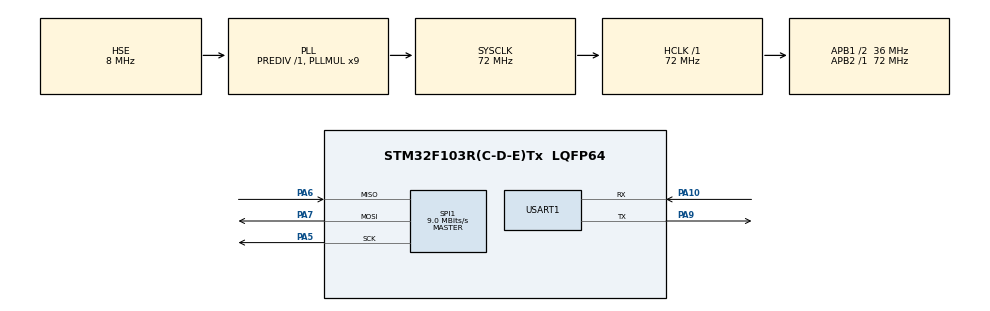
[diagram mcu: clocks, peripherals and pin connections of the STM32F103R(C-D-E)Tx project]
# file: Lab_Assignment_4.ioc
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Mcu.Family=STM32F1
Mcu.Name=STM32F103R(C-D-E)Tx
Mcu.Package=LQFP64
NVIC.PriorityGroup=NVIC_PRIORITYGROUP_4
PA10.Mode=Asynchronous
PA10.Signal=USART1_RX
PA13.Mode=Serial_Wire
PA13.Signal=SYS_JTMS-SWDIO
PA14.Mode=Serial_Wire
PA14.Signal=SYS_JTCK-SWCLK
PA5.Mode=Full_Duplex_Master
PA5.Signal=SPI1_SCK
PA6.Mode=Full_Duplex_Master
PA6.Signal=SPI1_MISO
PA7.Mode=Full_Duplex_Master
PA7.Signal=SPI1_MOSI
PA9.Mode=Asynchronous
PA9.Signal=USART1_TX
PD0-OSC_IN.Mode=HSE-External-Oscillator
PD0-OSC_IN.Signal=RCC_OSC_IN
PD1-OSC_OUT.Mode=HSE-External-Oscillator
PD1-OSC_OUT.Signal=RCC_OSC_OUT
ProjectManager.HeapSize=0x200
ProjectManager.StackSize=0x400
ProjectManager.TargetToolchain=STM32CubeIDE
RCC.AHBFreq_Value=72000000
RCC.APB1CLKDivider=RCC_HCLK_DIV2
RCC.APB1Freq_Value=36000000
RCC.APB1TimFreq_Value=72000000
RCC.APB2Freq_Value=72000000
RCC.APB2TimFreq_Value=72000000
RCC.HCLKFreq_Value=72000000
RCC.PLLMUL=RCC_PLL_MUL9
RCC.PLLSourceVirtual=RCC_PLLSOURCE_HSE
RCC.SYSCLKFreq_VALUE=72000000
RCC.SYSCLKSource=RCC_SYSCLKSOURCE_PLLCLK
RCC.USBFreq_Value=72000000
SPI1.BaudRatePrescaler=SPI_BAUDRATEPRESCALER_8
SPI1.CalculateBaudRate=9.0 MBits/s
SPI1.Direction=SPI_DIRECTION_2LINES
SPI1.Mode=SPI_MODE_MASTER
SPI1.VirtualType=VM_MASTER
USART1.VirtualMode=VM_ASYNC
board=custom

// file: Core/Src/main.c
/* USER CODE BEGIN Header */
/**
  ******************************************************************************
  * @file           : main.c
  * @brief          : Main program body
  ******************************************************************************
  * @attention
  *
  * Copyright (c) 2022 STMicroelectronics.
  * All rights reserved.
  *
  * This software is licensed under terms that can be found in the LICENSE file
  * in the root directory of this software component.
  * If no LICENSE file comes with this software, it is provided AS-IS.
  *
  ******************************************************************************
  */
/* USER CODE END Header */
#include "main.h"

/* USER CODE BEGIN Includes */

/* Private includes ----------------------------------------------------------*/
/* USER CODE BEGIN Includes */
#include "sys.h"
#include "delay.h"
#include "stdlib.h"
//#include "usart.h"
#include "led.h"
#include "key.h"
#include "lcd.h"
//#include "usmart.h"
#include "touch.h"
#include "24cxx.h"
#include "24l01.h" //通信驱动 基于spi进行通信
/* USER CODE END Includes */

/* USER CODE BEGIN PD */
unsigned char DATA_TO_SEND[800];
int state_num = 0;
u8 STATE[30];
UART_HandleTypeDef huart1;

const unsigned char gImage_barrier[2088] = { 0X00,0X10,0X1A,0X00,0X28,0X00,0X01,0X1B,
0X00,0X00,0XFF,0XFF,0XFF,0XFF,0XFF,0XFF,0XFF,0XFF,0XFF,0XFF,0XFF,0XFF,0XFF,0XFF,
0XFF,0XFF,0XFF,0XFF,0XFF,0XFF,0XFF,0XFF,0XFF,0XFF,0XFF,0XFF,0XFF,0XFF,0XFF,0XFF,
0XFF,0XFF,0XFF,0XFF,0XFF,0XFF,0XFF,0XFF,0XFF,0XFF,0XFF,0XFF,0XFF,0XFF,0XFF,0XFF,
0XFF,0XFF,0XFF,0XFF,0XFF,0XFF,0X00,0X00,0XFF,0XFF,0XFF,0XFF,0XFF,0XFF,0XFF,0XFF,
0XFF,0XFF,0XFF,0XFF,0XFF,0XFF,0XFF,0XFF,0XFF,0XFF,0XFF,0XFF,0XFF,0XFF,0XFF,0XFF,
0XFF,0XFF,0XFF,0XFF,0XFF,0XFF,0XFF,0XFF,0XFF,0XFF,0XFF,0XFF,0XFF,0XFF,0XFF,0XFF,
0XFF,0XFF,0XFF,0XFF,0XFF,0XFF,0XFF,0XFF,0XFF,0XFF,0X00,0X00,0XFF,0XFF,0XFF,0XFF,
0XFF,0XFF,0XFF,0XFF,0XFF,0XFF,0XFF,0XFF,0XFF,0XFF,0XFF,0XFF,0XFF,0XFF,0XFF,0XFF,
0XFF,0XFF,0XFF,0XFF,0XFF,0XFF,0X65,0X29,0XFF,0XFF,0XFF,0XFF,0XFF,0XFF,0XFF,0XFF,
0XFF,0XFF,0XFF,0XFF,0XFF,0XFF,0XFF,0XFF,0XFF,0XFF,0XFF,0XFF,0XFF,0XFF,0XFF,0XFF,
0X00,0X00,0XFF,0XFF,0XFF,0XFF,0XFF,0XFF,0XFF,0XFF,0XFF,0XFF,0XFF,0XFF,0XFF,0XFF,
0XFF,0XFF,0XFF,0XFF,0XF7,0XBD,0XFF,0XFF,0X28,0X42,0XFF,0XFF,0XFF,0XFF,0X7D,0XAF,
0X5C,0X4F,0XFF,0XFF,0XFF,0XFF,0XFF,0XFF,0XFF,0XFF,0XFF,0XFF,0XFF,0XFF,0XFF,0XFF,
0XFF,0XFF,0XFF,0XFF,0XFF,0XFF,0X00,0X00,0XFF,0XFF,0XFF,0XFF,0XFF,0XFF,0XFF,0XFF,
0XFF,0XFF,0XFF,0XFF,0XFF,0XFF,0X71,0X8C,0XFF,0XFF,0XFF,0XFF,0XD7,0XBD,0XFF,0XFF,
0XF7,0X45,0XAE,0X03,0XAE,0X03,0X4F,0X0C,0X05,0X5A,0XFF,0XFF,0XFF,0XFF,0XFF,0XFF,
0XFF,0XFF,0XFF,0XFF,0XFF,0XFF,0XFF,0XFF,0XFF,0XFF,0X00,0X00,0XFF,0XFF,0XFF,0XFF,
0XFF,0XFF,0XFF,0XFF,0XFF,0XFF,0X9E,0XF7,0X00,0X00,0XFF,0XFF,0XFF,0XFF,0X00,0X00,
0XFF,0XFF,0XFF,0XFF,0XFF,0XFF,0X30,0X14,0X2A,0X02,0X8B,0X33,0X4C,0X4B,0XFF,0XFF,
0XFF,0XFF,0XFF,0XFF,0XFF,0XFF,0XFF,0XFF,0XFF,0XFF,0XFF,0XFF,0XFF,0XFF,0XFF,0XFF,
0X00,0X00,0XFF,0XFF,0XFF,0XFF,0XFF,0XFF,0XFF,0XFF,0X00,0X00,0XFF,0XFF,0XFF,0XFF,
0X0D,0X8C,0X2C,0X63,0XFF,0XFF,0XFF,0XFF,0XFF,0XFF,0X49,0X02,0X89,0X02,0XE7,0X7A,
0X00,0X00,0XFF,0XFF,0XFF,0XFF,0XFF,0XFF,0XFF,0XFF,0XFF,0XFF,0XFF,0XFF,0XFF,0XFF,
0XFF,0XFF,0XFF,0XFF,0X00,0X00,0XFF,0XFF,0XFF,0XFF,0XFF,0XFF,0X00,0X00,0XFF,0XFF,
0XFF,0XFF,0XFF,0XFF,0X31,0X5C,0XEF,0X7B,0XFF,0XFF,0XFF,0XFF,0X6A,0X42,0X69,0X01,
0X72,0XDE,0X86,0X3A,0X0D,0X23,0XFF,0XFF,0XFF,0XFF,0XFF,0XFF,0XFF,0XFF,0XFF,0XFF,
0XFF,0XFF,0XFF,0XFF,0XFF,0XFF,0XFF,0XFF,0XFF,0XFF,0X00,0X00,0XFF,0XFF,0XCE,0XD5,
0XA2,0X10,0XFF,0XFF,0XFF,0XFF,0XFF,0XFF,0XCF,0X5B,0X4E,0X4B,0X11,0X3C,0X46,0X21,
0X0E,0X8C,0X0D,0XC5,0X66,0X62,0XE5,0X00,0XFF,0XFF,0XFF,0XFF,0XFF,0XFF,0XFF,0XFF,
0XFF,0XFF,0XFF,0XFF,0XFF,0XFF,0XFF,0XFF,0XFF,0XFF,0XFF,0XFF,0XFF,0XFF,0XFF,0XFF,
0X4D,0XF6,0X69,0X83,0XFF,0XFF,0XFF,0XFF,0XFF,0XFF,0XFE,0XFF,0X59,0XAE,0X07,0X32,
0X62,0X00,0X75,0X85,0XA5,0X31,0X00,0X39,0X27,0X4A,0XFF,0XFF,0X00,0X00,0XFF,0XFF,
0XFF,0XFF,0XFF,0XFF,0XFF,0XFF,0XFF,0XFF,0XFF,0XFF,0XFF,0XFF,0XFF,0XFF,0XFF,0XFF,
0XFF,0XFF,0XFF,0XFF,0XCC,0XF5,0X00,0X00,0XFF,0XFF,0XFF,0XFF,0XFF,0XFF,0X3D,0XEF,
0XAE,0X6B,0XA6,0X9B,0XA6,0X29,0X67,0X19,0XA7,0X21,0X62,0X29,0X84,0X21,0XFF,0XFF,
0XFF,0XFF,0XFF,0XFF,0XFF,0XFF,0XFF,0XFF,0XFF,0XFF,0X18,0XC6,0XFF,0XFF,0XFF,0XFF,
0XFF,0XFF,0XFF,0XFF,0XFF,0XFF,0X55,0XE6,0XAD,0XED,0X00,0X00,0XFF,0XFF,0X88,0X19,
0X2A,0X0A,0X2A,0X39,0XE9,0X6A,0XA7,0X3A,0X66,0X21,0X88,0X09,0XA8,0X01,0X87,0X11,
0XFF,0XFF,0X66,0X11,0XFF,0XFF,0XFF,0XFF,0XFF,0XFF,0XFF,0XFF,0X8F,0XF5,0X00,0X00,
0XFF,0XFF,0XFF,0XFF,0XFF,0XFF,0XFF,0XFF,0XFF,0XFF,0XC9,0XAB,0X89,0XCC,0X54,0XA5,
0X04,0X09,0X6F,0X2B,0X33,0X3C,0X6D,0X63,0X51,0X54,0X68,0X11,0XE2,0X18,0X09,0X12,
0X88,0X01,0XFF,0XFF,0X88,0X21,0X00,0X00,0XFF,0XFF,0XFF,0XFF,0XFF,0XFF,0XFF,0XFF,
0X89,0XDC,0XE2,0X82,0XFF,0XFF,0XFF,0XFF,0XFF,0XFF,0XFF,0XFF,0XFF,0XFF,0X83,0X7A,
0XC6,0XAB,0X87,0X19,0X4B,0X0A,0XCD,0X1A,0X75,0X1C,0X6F,0X3B,0X0F,0X23,0XA8,0X29,
0X86,0X21,0X4B,0X12,0XC9,0X01,0XFF,0XFF,0X47,0X01,0X00,0X00,0XFF,0XFF,0XFF,0XFF,
0XFF,0XFF,0XFF,0XFF,0X69,0XD4,0XA0,0X72,0XFF,0XFF,0XFF,0XFF,0XFF,0XFF,0XFF,0XFF,
0XFF,0XFF,0X00,0X7A,0X0B,0XDD,0X45,0X11,0X0A,0X0A,0X10,0X1B,0X2F,0X54,0X89,0X4A,
0XC7,0X39,0X47,0X5A,0X89,0X4A,0X2F,0X1B,0XFF,0XFF,0X6E,0X43,0X6C,0X0A,0XC5,0X00,
0XFF,0XFF,0XFF,0XFF,0XFF,0XFF,0X0A,0XA4,0X43,0XAB,0X81,0X72,0XFF,0XFF,0XFF,0XFF,
0XFF,0XFF,0XFF,0XFF,0XFF,0XFF,0X80,0X61,0X33,0XFF,0X67,0X2A,0X2B,0X12,0X6D,0X3B,
0X2C,0XD4,0X2C,0XBC,0XCB,0X93,0XA9,0X52,0X6E,0X23,0XFF,0XFF,0X91,0X13,0X8F,0X33,
0XAF,0X1B,0X00,0X00,0XFF,0XFF,0XFF,0XFF,0XFF,0XFF,0X07,0XBC,0XC1,0X92,0X82,0X62,
0XFF,0XFF,0XFF,0XFF,0XFF,0XFF,0XFF,0XFF,0XFF,0XFF,0XE0,0X79,0XE9,0XDC,0X67,0X3A,
0X69,0X22,0XAB,0X5B,0XEC,0XD4,0X4C,0X94,0X2B,0XB4,0XEB,0X93,0XEF,0X23,0XFF,0XFF,
0X0F,0X13,0X8F,0X23,0X4D,0X23,0X00,0X00,0XFF,0XFF,0X4F,0XF7,0XA8,0XCC,0X45,0X9B,
0X60,0X7A,0X00,0X00,0XFF,0XFF,0XFF,0XFF,0XFF,0XFF,0XFF,0XFF,0XFF,0XFF,0X41,0X82,
0X87,0XA3,0X63,0X42,0XA8,0X6A,0X48,0X7B,0XEA,0XEC,0XCB,0XE4,0X6B,0XBC,0X49,0X63,
0XFF,0XFF,0XA5,0XAB,0XAB,0X12,0XED,0X1A,0XCC,0X42,0X8A,0X73,0X6E,0XF6,0X6B,0XE5,
0X24,0XA3,0X64,0XAB,0X41,0X72,0X29,0X3A,0XFF,0XFF,0XFF,0XFF,0XFF,0XFF,0XFF,0XFF,
0XFF,0XFF,0X08,0X7B,0XC5,0X82,0X01,0X4A,0XA4,0X92,0XAA,0XA3,0XEC,0XEC,0XA5,0X6A,
0XCC,0X53,0XFF,0XFF,0X6F,0XD6,0XA3,0X8A,0XC7,0X11,0X06,0X32,0X0E,0XEE,0XEB,0XD4,
0X89,0XDC,0X62,0X82,0X86,0XAB,0X01,0X62,0X44,0X5A,0XA4,0X00,0XFF,0XFF,0XFF,0XFF,
0XFF,0XFF,0XFF,0XFF,0XCE,0X02,0XC4,0X21,0XC1,0X59,0X81,0X51,0XE5,0XA2,0X0A,0XBC,
0X89,0X93,0X27,0X6A,0XAA,0X8B,0XFF,0XFF,0XA4,0XB3,0X64,0X7A,0XA7,0X72,0X68,0XA3,
0XC7,0XB3,0XE7,0XB3,0X25,0X9B,0XE4,0X8A,0XC1,0X59,0X02,0X5A,0X24,0X29,0X45,0X4A,
0XFF,0XFF,0XFF,0XFF,0XD9,0X0D,0X50,0X03,0X8B,0X02,0X45,0X29,0XC3,0X59,0X21,0X39,
0XC6,0XAB,0X29,0X83,0X65,0X92,0X08,0XB4,0XFF,0XFF,0X02,0X62,0X42,0X6A,0XA2,0X51,
0X64,0X62,0XE3,0X49,0XA2,0X41,0XC4,0X82,0X66,0X5A,0XC4,0X11,0X03,0X11,0XEB,0X52,
0XE7,0X31,0X86,0X29,0XFF,0XFF,0X2F,0X03,0X76,0X04,0XD2,0X0B,0XFF,0XFF,0XFF,0XFF,
0XFF,0XFF,0XE2,0X10,0X62,0X72,0XA3,0X82,0X21,0X72,0XE0,0X40,0XFF,0XFF,0XE4,0X82,
0X20,0X41,0X60,0X31,0X45,0X29,0X47,0X52,0XA3,0X72,0XC6,0X41,0X05,0X11,0X05,0X01,
0XCC,0X52,0XE8,0X31,0X07,0X09,0X00,0X00,0XFF,0XFF,0XBB,0X5E,0X00,0X00,0X5D,0X1F,
0XFF,0XFF,0XFF,0XFF,0XFF,0XFF,0X26,0X11,0XA4,0X7A,0XC1,0X59,0X01,0X39,0XFF,0XFF,
0XE0,0X38,0XE0,0X38,0XC3,0X49,0X00,0X31,0XE1,0X20,0X02,0X19,0X0A,0X3A,0XA8,0X29,
0X65,0X10,0X4A,0X42,0XC9,0X21,0X45,0X11,0X6B,0X02,0X00,0X00,0XFF,0XFF,0X00,0X00,
0XFF,0XFF,0XFF,0XFF,0XFF,0XFF,0XFF,0XFF,0XFF,0XFF,0X87,0X21,0XE2,0X59,0X64,0X29,
0XFF,0XFF,0XA4,0X49,0XC0,0X38,0XA3,0X08,0XC3,0X00,0XC4,0X00,0XA8,0X11,0X2A,0X32,
0XA9,0X21,0X46,0X19,0X46,0X21,0X46,0X21,0X6B,0X0A,0XCC,0X02,0X8C,0X02,0X4B,0X0A,
0XFF,0XFF,0XFF,0XFF,0XFF,0XFF,0XFF,0XFF,0XFF,0XFF,0XFF,0XFF,0XFF,0XFF,0XDF,0XFF,
0XA3,0X51,0X05,0X21,0XFF,0XFF,0XE1,0X30,0X65,0X31,0X09,0X3A,0XE9,0X31,0X8B,0X42,
0X8C,0X52,0X2A,0X3A,0X88,0X21,0X89,0X11,0X08,0X3A,0XE6,0X72,0X46,0X32,0X2A,0X02,
0X0B,0X02,0X00,0X00,0XFF,0XFF,0XFF,0XFF,0XFF,0XFF,0XFF,0XFF,0XFF,0XFF,0XFF,0XFF,
0XFF,0XFF,0XFF,0XFF,0X86,0X31,0XFF,0XFF,0XA4,0X51,0X83,0X18,0XE6,0X00,0XA5,0X00,
0XA5,0X08,0X0A,0X0A,0XE8,0X09,0XC7,0X09,0XC5,0X09,0XAA,0X09,0XE9,0X11,0X85,0X19,
0XA6,0X29,0X8B,0X02,0X0A,0X02,0X00,0X00,0XFF,0XFF,0XFF,0XFF,0XFF,0XFF,0XFF,0XFF,
0XFF,0XFF,0XFF,0XFF,0XFF,0XFF,0XFF,0XFF,0XFF,0XFF,0X83,0X00,0XA3,0X10,0XC2,0X28,
0X06,0X01,0XE9,0X21,0XE7,0X08,0XB6,0X02,0X0E,0X02,0X29,0X0A,0XC7,0X09,0XC5,0X09,
0XA8,0X11,0XA7,0X09,0X86,0X01,0XED,0X0A,0XED,0X02,0XE7,0X39,0XFF,0XFF,0XFF,0XFF,
0XFF,0XFF,0XFF,0XFF,0XFF,0XFF,0XFF,0XFF,0XFF,0XFF,0XFF,0XFF,0XFF,0XFF,0X25,0X19,
0X67,0X21,0X86,0X29,0X0A,0X32,0X07,0X09,0XC6,0X00,0X6D,0X02,0XB0,0X02,0X6E,0X02,
0X29,0X0A,0X07,0X0A,0XA5,0X09,0X87,0X09,0XA7,0X01,0X90,0X13,0XEE,0X02,0XFF,0XFF,
0XFF,0XFF,0XFF,0XFF,0XFF,0XFF,0XFF,0XFF,0XFF,0XFF,0X2C,0X63,0X00,0X00,0XFF,0XFF,
0X49,0X0A,0XA7,0X21,0X06,0X11,0X47,0X19,0XE6,0X00,0X68,0X01,0XCA,0X01,0XA9,0X01,
0XAD,0X02,0X70,0X02,0X4C,0X02,0X28,0X0A,0XE6,0X09,0X86,0X09,0XA7,0X09,0XD1,0X03,
0X2E,0X0B,0XFF,0XFF,0XFF,0XFF,0XFF,0XFF,0XFF,0XFF,0XFF,0XFF,0XFF,0XFF,0XFF,0XFF,
0XFF,0XFF,0XFF,0XFF,0XFF,0XFF,0XA6,0X19,0X80,0X18,0XE4,0X08,0X25,0X19,0XC9,0X09,
0X6C,0X0A,0X49,0X01,0XC9,0X02,0X8D,0X02,0X6E,0X02,0X49,0X02,0XE7,0X09,0XA5,0X01,
0X88,0X01,0XF0,0X03,0X6F,0X03,0XFF,0XFF,0XFF,0XFF,0XFF,0XFF,0XFF,0XFF,0XFF,0XFF,
0XFF,0XFF,0XFF,0XFF,0XFF,0XFF,0XFF,0XFF,0XFF,0XFF,0XFF,0XFF,0X00,0X39,0X21,0X19,
0X42,0X29,0X65,0X01,0X0A,0X02,0X89,0X01,0X48,0X02,0X6A,0X02,0X2C,0X02,0X28,0X02,
0X07,0X0A,0XA5,0X01,0XCA,0X01,0X53,0X04,0X00,0X00,0XFF,0XFF,0XFF,0XFF,0XFF,0XFF,
0XFF,0XFF,0XFF,0XFF,0XFF,0XFF,0XFF,0XFF,0XFF,0XFF,0XFF,0XFF,0XFF,0XFF,0XFF,0XFF,
0X00,0X00,0XA5,0X19,0XC5,0X09,0X83,0X31,0XE9,0X01,0XC9,0X01,0X4A,0X02,0X6B,0X02,
0X2E,0X02,0X0A,0X02,0X07,0X02,0X85,0X01,0XDA,0X04,0XF8,0X04,0X90,0X13,0XFF,0XFF,
0XFF,0XFF,0XFF,0XFF,0XFF,0XFF,0XFF,0XFF,0XFF,0XFF,0XFF,0XFF,0XFF,0XFF,0XFF,0XFF,
0XFF,0XFF,0XFF,0XFF,0XFF,0XFF,0XFF,0XFF,0XFF,0XFF,0X00,0X00,0X8E,0X73,0XFF,0XFF,
0XFF,0XFF,0X9E,0XEF,0X4D,0X02,0X00,0X00,0X7D,0XEF,0X3C,0X06,0X98,0X04,0XD8,0X04,
0X13,0X04,0XFF,0XFF,0XFF,0XFF,0XFF,0XFF,0XFF,0XFF,0XFF,0XFF,0XFF,0XFF,0XFF,0XFF,
0XFF,0XFF,0XFF,0XFF,0XFF,0XFF,0XFF,0XFF,0XFF,0XFF,0XFF,0XFF,0XFF,0XFF,0XFF,0XFF,
0XFF,0XFF,0XFF,0XFF,0XFF,0XFF,0X2B,0X02,0X4A,0X02,0XFF,0XFF,0XFF,0XFF,0XA7,0X01,
0X89,0X01,0X79,0X05,0X91,0X03,0XFF,0XFF,0XFF,0XFF,0XFF,0XFF,0XFF,0XFF,0XFF,0XFF,
0XFF,0XFF,0XFF,0XFF,0XFF,0XFF,0XFF,0XFF,0XFF,0XFF,0XFF,0XFF,0XFF,0XFF,0XFF,0XFF,
0XFF,0XFF,0XFF,0XFF,0XFF,0XFF,0XFF,0XFF,0XFC,0XD6,0XCD,0X01,0X00,0X00,0XFF,0XFF,
0X9A,0X46,0X87,0X01,0XF0,0X6B,0X6F,0X03,0X34,0X0C,0XFF,0XFF,0XFF,0XFF,0XFF,0XFF,
0XFF,0XFF,0XFF,0XFF,0XFF,0XFF,0XFF,0XFF,0XFF,0XFF,0XFF,0XFF,0XFF,0XFF,0XFF,0XFF,
0XFF,0XFF,0XFF,0XFF,0XFF,0XFF,0XFF,0XFF,0X29,0X02,0X2F,0X02,0X00,0X00,0X00,0X00,
0XFF,0XFF,0XFF,0XFF,0XA5,0X01,0XC5,0X00,0X35,0X3D,0X3B,0X06,0X13,0X04,0XBA,0XD6,
0XFF,0XFF,0XFF,0XFF,0XFF,0XFF,0XFF,0XFF,0XFF,0XFF,0XFF,0XFF,0XFF,0XFF,0XFF,0XFF,
0XFF,0XFF,0XFF,0XFF,0XFF,0XFF,0XFF,0XFF,0XFF,0XFF,0X4F,0X2B,0X00,0X00,0X5D,0XEF,
0XFF,0XFF,0XFF,0XFF,0XFF,0XFF,0XFF,0XFF,0XAB,0X09,0X2A,0X12,0X00,0X00,0X00,0X00,
0X6E,0X03,0XBA,0XD6,0XFF,0XFF,0XFF,0XFF,0XFF,0XFF,0XFF,0XFF,0XFF,0XFF,0XFF,0XFF,
0XFF,0XFF,0XFF,0XFF,0XFF,0XFF,0XFF,0XFF,0XFF,0XFF,0XED,0X22,0XFF,0XFF,0XFF,0XFF,
0XFF,0XFF,0XFF,0XFF,0XFF,0XFF,0XFF,0XFF,0XFF,0XFF,0XAB,0X01,0X08,0X0A,0X0D,0X02,
0XFF,0XFF,0XFF,0XFF,0X00,0X00,0XFF,0XFF,0XFF,0XFF,0XFF,0XFF,0XFF,0XFF,0XFF,0XFF,
0XFF,0XFF,0XFF,0XFF,0XFF,0XFF,0XFF,0XFF,0XFF,0XFF,0XFF,0XFF,0XFF,0XFF,0XFF,0XFF,
0XFF,0XFF,0XFF,0XFF,0XFF,0XFF,0XFF,0XFF,0XFF,0XFF,0XFF,0XFF,0X89,0X01,0X0B,0X1A,
0X6F,0X2A,0X8A,0X09,0XEF,0X7B,0XFF,0XFF,0X00,0X00,0XFF,0XFF,0XFF,0XFF,0XFF,0XFF,
0XFF,0XFF,0XFF,0XFF,0XFF,0XFF,0XFF,0XFF,0XFF,0XFF,0XFF,0XFF,0XFF,0XFF,0XFF,0XFF,
0XFF,0XFF,0XFF,0XFF,0XFF,0XFF,0XFF,0XFF,0XFF,0XFF,0XFF,0XFF,0X69,0X4A,0X96,0XB5,
0XFF,0XFF,0XFF,0XFF,0XFF,0XFF,0XFF,0XFF,0X7D,0XEF,0XFF,0XFF,0XFF,0XFF,0XFF,0XFF,
};
const unsigned char gImage_player[1768] = { 0X00,0X10,0X28,0X00,0X16,0X00,0X01,0X1B,
0X00,0X00,0XFF,0XFF,0XFF,0XFF,0XFF,0XFF,0XFF,0XFF,0XFF,0XFF,0XFF,0XFF,0XFF,0XFF,
0XFF,0XFF,0XFF,0XFF,0XFF,0XFF,0XFF,0XFF,0XFF,0XFF,0XFF,0XFF,0XFF,0XFF,0XFF,0XFF,
0XFF,0XFF,0XFF,0XFF,0XFF,0XFF,0XFF,0XFF,0XFF,0XFF,0XFF,0XFF,0XFF,0XFF,0XFF,0XFF,
0XFF,0XFF,0XFF,0XFF,0XFF,0XFF,0XFF,0XFF,0XFF,0XFF,0XFF,0XFF,0XFF,0XFF,0XFF,0XFF,
0XFF,0XFF,0XFF,0XFF,0XFF,0XFF,0XFF,0XFF,0XFF,0XFF,0XFF,0XFF,0XFF,0XFF,0XFF,0XFF,
0XFF,0XFF,0X00,0X00,0X00,0X00,0XFF,0XFF,0XFF,0XFF,0XFF,0XFF,0XFF,0XFF,0XFF,0XFF,
0XFF,0XFF,0XFF,0XFF,0XFF,0XFF,0XFF,0XFF,0XFF,0XFF,0XFF,0XFF,0XFF,0XFF,0XFF,0XFF,
0XFF,0XFF,0XFF,0XFF,0XFF,0XFF,0XFF,0XFF,0XFF,0XFF,0XFF,0XFF,0XFF,0XFF,0XFF,0XFF,
0XFF,0XFF,0XDA,0XDE,0X58,0XC6,0XCC,0X29,0X24,0X42,0XF1,0X53,0XFF,0XFF,0XFF,0XFF,
0XFF,0XFF,0XFF,0XFF,0XFF,0XFF,0XFF,0XFF,0XFF,0XFF,0XFF,0XFF,0XFF,0XFF,0XFF,0XFF,
0XFF,0XFF,0XFF,0XFF,0XFF,0XFF,0X00,0X00,0X00,0X00,0XFF,0XFF,0XFF,0XFF,0XFF,0XFF,
0XFF,0XFF,0XFF,0XFF,0XFF,0XFF,0XFF,0XFF,0XFF,0XFF,0XFF,0XFF,0XFF,0XFF,0XFF,0XFF,
0XFF,0XFF,0XFF,0XFF,0XFF,0XFF,0XFF,0XFF,0XFF,0XFF,0XFF,0XFF,0XFF,0XFF,0XFF,0XFF,
0X58,0X85,0X6D,0X32,0XA8,0X19,0XCE,0X73,0X2D,0XA5,0X48,0X42,0XFF,0XFF,0XFF,0XFF,
0XFF,0XFF,0XFF,0XFF,0XFF,0XFF,0XFF,0XFF,0XFF,0XFF,0XFF,0XFF,0XFF,0XFF,0XFF,0XFF,
0XFF,0XFF,0XFF,0XFF,0XFF,0XFF,0XFF,0XFF,0XFF,0XFF,0X00,0X00,0X00,0X00,0XFF,0XFF,
0XFF,0XFF,0XFF,0XFF,0XFF,0XFF,0XFF,0XFF,0XFF,0XFF,0XFF,0XFF,0XFF,0XFF,0XFF,0XFF,
0XFF,0XFF,0XFF,0XFF,0XFF,0XFF,0XFF,0XFF,0XFF,0XFF,0X71,0X43,0XF4,0X5B,0XF0,0X3A,
0XCF,0X3A,0X4B,0X3A,0X00,0X00,0X4E,0X53,0X03,0X19,0XA1,0X39,0X00,0X00,0XFF,0XFF,
0XFF,0XFF,0XFF,0XFF,0XFF,0XFF,0XFF,0XFF,0XFF,0XFF,0XFF,0XFF,0XFF,0XFF,0XFF,0XFF,
0XFF,0XFF,0XFF,0XFF,0XFF,0XFF,0XFF,0XFF,0XFF,0XFF,0XFF,0XFF,0XFF,0XFF,0X00,0X00,
0X00,0X00,0XFF,0XFF,0XFF,0XFF,0XFF,0XFF,0XFF,0XFF,0XFF,0XFF,0XFF,0XFF,0XFF,0XFF,
0XFF,0XFF,0XFF,0XFF,0XFF,0XFF,0X00,0X00,0XFF,0XFF,0X7E,0XEF,0X11,0X4B,0XCF,0X42,
0XCF,0X3A,0X00,0X00,0XFF,0XFF,0X2F,0X53,0XA2,0X18,0X61,0X31,0X00,0X00,0XFF,0XFF,
0XFF,0XFF,0XFF,0XFF,0XFF,0XFF,0XFF,0XFF,0XFF,0XFF,0XFF,0XFF,0XFF,0XFF,0XFF,0XFF,
0XFF,0XFF,0XFF,0XFF,0XFF,0XFF,0XFF,0XFF,0XFF,0XFF,0XFF,0XFF,0XFF,0XFF,0XFF,0XFF,
0XFF,0XFF,0X00,0X00,0X00,0X00,0XFF,0XFF,0XFF,0XFF,0XFF,0XFF,0XFF,0XFF,0XFF,0XFF,
0XFF,0XFF,0XFF,0XFF,0XFF,0XFF,0XFF,0XFF,0XFF,0XFF,0X58,0X95,0X6F,0X32,0XCB,0X19,
0XCA,0X21,0X1D,0XD7,0X9E,0XF7,0X28,0X62,0XB6,0XDD,0XFF,0XFF,0XFF,0XFF,0XFF,0XFF,
0XFF,0XFF,0XFF,0XFF,0XFF,0XFF,0XFF,0XFF,0XFF,0XFF,0XFF,0XFF,0XFF,0XFF,0XFF,0XFF,
0XFF,0XFF,0XFF,0XFF,0XFF,0XFF,0XFF,0XFF,0XFF,0XFF,0XFF,0XFF,0XFF,0XFF,0XFF,0XFF,
0XFF,0XFF,0XFF,0XFF,0XFF,0XFF,0X00,0X00,0X00,0X00,0XFF,0XFF,0XFF,0XFF,0XFF,0XFF,
0XFF,0XFF,0XFF,0XFF,0XFF,0XFF,0XFF,0XFF,0XDF,0XFF,0X8E,0X32,0X93,0X5B,0X0A,0X2A,
0XC7,0X00,0XA9,0X21,0X0B,0X2A,0XFF,0XFF,0XFF,0XFF,0X00,0X00,0XFF,0XFF,0XFF,0XFF,
0XFF,0XFF,0XFF,0XFF,0XFF,0XFF,0XFF,0XFF,0XFF,0XFF,0XFF,0XFF,0XFF,0XFF,0XFF,0XFF,
0XFF,0XFF,0XFF,0XFF,0XFF,0XFF,0XFF,0XFF,0XFF,0XFF,0XFF,0XFF,0XFF,0XFF,0XFF,0XFF,
0XFF,0XFF,0XFF,0XFF,0XFF,0XFF,0XFF,0XFF,0XFF,0XFF,0X00,0X00,0XFF,0XFF,0XFF,0XFF,
0XFF,0XFF,0XFF,0XFF,0XFF,0XFF,0XFF,0XFF,0XEA,0X29,0X6D,0X3A,0XCA,0X21,0X2F,0X4B,
0X27,0X09,0X0F,0X4B,0XFF,0XFF,0XE2,0X10,0XC6,0X31,0X8C,0X42,0X54,0X8D,0XFF,0XFF,
0XFF,0XFF,0XFF,0XFF,0XFF,0XFF,0XFF,0XFF,0XFF,0XFF,0XFF,0XFF,0XFF,0XFF,0XFF,0XFF,
0XFF,0XFF,0XFF,0XFF,0XFF,0XFF,0XFF,0XFF,0XFF,0XFF,0XFF,0XFF,0XFF,0XFF,0XFF,0XFF,
0XFF,0XFF,0XFF,0XFF,0XFF,0XFF,0XFF,0XFF,0XFF,0XFF,0XFF,0XFF,0X00,0X00,0X00,0X00,
0XFF,0XFF,0XFF,0XFF,0XFF,0XFF,0XBB,0XD6,0X26,0X11,0X12,0X5C,0XA9,0X19,0XCA,0X21,
0XFF,0XFF,0XFF,0XFF,0XA5,0X08,0XA9,0X19,0XED,0X42,0X2C,0X2A,0X0C,0X1A,0X46,0X01,
0X00,0X00,0X00,0X00,0X00,0X00,0XFF,0XFF,0XFF,0XFF,0XFF,0XFF,0XFF,0XFF,0XFF,0XFF,
0XFF,0XFF,0XFF,0XFF,0XFF,0XFF,0XFF,0XFF,0XFF,0XFF,0XFF,0XFF,0XFF,0XFF,0XFF,0XFF,
0XFF,0XFF,0XFF,0XFF,0XFF,0XFF,0XFF,0XFF,0XFF,0XFF,0XFF,0XFF,0XFF,0XFF,0XFF,0XFF,
0X00,0X00,0X00,0X00,0XFF,0XFF,0X9E,0XE7,0X18,0X7D,0XE9,0X19,0XFF,0XFF,0XFF,0XFF,
0X69,0X11,0X48,0X11,0X85,0X00,0X6D,0X3A,0XB6,0X74,0X21,0X21,0XC3,0X31,0X0A,0X02,
0X8A,0X52,0XFF,0XFF,0XFF,0XFF,0XFF,0XFF,0XFF,0XFF,0XFF,0XFF,0XFF,0XFF,0XFF,0XFF,
0XFF,0XFF,0XFF,0XFF,0XFF,0XFF,0XFF,0XFF,0XFF,0XFF,0XFF,0XFF,0XFF,0XFF,0XFF,0XFF,
0XFF,0XFF,0XFF,0XFF,0XFF,0XFF,0XFF,0XFF,0XFF,0XFF,0XFF,0XFF,0XFF,0XFF,0XFF,0XFF,
0XFF,0XFF,0XFF,0XFF,0X54,0X6C,0X5B,0XB6,0XFF,0XFF,0XFF,0XFF,0X96,0X7C,0X2E,0X2A,
0X8A,0X19,0XE7,0X08,0XCA,0X21,0XE7,0X00,0X71,0X53,0XCF,0X42,0X25,0X09,0XC9,0X09,
0X00,0X00,0XFF,0XFF,0XFF,0XFF,0XFF,0XFF,0XFF,0XFF,0XFF,0XFF,0XFF,0XFF,0XFF,0XFF,
0XFF,0XFF,0XFF,0XFF,0XFF,0XFF,0XFF,0XFF,0XFF,0XFF,0XFF,0XFF,0XFF,0XFF,0XFF,0XFF,
0XFF,0XFF,0XFF,0XFF,0XFF,0XFF,0XFF,0XFF,0XFF,0XFF,0XFF,0XFF,0XFF,0XFF,0XFF,0XFF,
0XFF,0XFF,0X5A,0XBE,0XFF,0XFF,0XFF,0XFF,0X61,0X00,0X83,0X00,0X10,0X43,0XCD,0X19,
0X71,0X4B,0X48,0X11,0X48,0X19,0X08,0X09,0X06,0X11,0X89,0X11,0X83,0X00,0XCA,0X01,
0XFF,0XFF,0XFF,0XFF,0XFF,0XFF,0XFF,0XFF,0XFF,0XFF,0XFF,0XFF,0XFF,0XFF,0XFF,0XFF,
0XFF,0XFF,0XFF,0XFF,0XFF,0XFF,0XFF,0XFF,0XFF,0XFF,0XFF,0XFF,0XFF,0XFF,0XFF,0XFF,
0XFF,0XFF,0XFF,0XFF,0XFF,0XFF,0XFF,0XFF,0XFF,0XFF,0XFF,0XFF,0XFF,0XFF,0XFF,0XFF,
0XFF,0XFF,0XFF,0XFF,0X45,0X19,0X82,0X08,0X65,0X19,0X03,0X11,0X06,0X09,0XF4,0X4B,
0X00,0X00,0XC4,0X00,0X06,0X09,0X62,0X00,0XE5,0X08,0X27,0X11,0X26,0X09,0XEB,0X09,
0XFF,0XFF,0XFF,0XFF,0XFF,0XFF,0XFF,0XFF,0XFF,0XFF,0XFF,0XFF,0XFF,0XFF,0XFF,0XFF,
0XFF,0XFF,0XFF,0XFF,0XFF,0XFF,0XFF,0XFF,0XFF,0XFF,0XFF,0XFF,0XFF,0XFF,0XFF,0XFF,
0XFF,0XFF,0XFF,0XFF,0XFF,0XFF,0XFF,0XFF,0XFF,0XFF,0XFF,0XFF,0XFF,0XFF,0XFF,0XFF,
0X4C,0X94,0X65,0X5A,0XE4,0X10,0XE4,0X08,0X28,0X32,0X00,0X00,0X00,0X00,0XFF,0XFF,
0X00,0X00,0XB2,0X33,0XFF,0XFF,0XE4,0X00,0X49,0X11,0X0B,0X2A,0XC4,0X08,0X4D,0X22,
0X00,0X00,0XFF,0XFF,0XFF,0XFF,0XFF,0XFF,0XFF,0XFF,0XFF,0XFF,0XFF,0XFF,0XFF,0XFF,
0XFF,0XFF,0XFF,0XFF,0XFF,0XFF,0XFF,0XFF,0XFF,0XFF,0XFF,0XFF,0X3A,0XA6,0XF2,0X63,
0X10,0X4B,0X00,0X00,0X00,0X00,0XFF,0XFF,0XFF,0XFF,0XFF,0XFF,0XFF,0XFF,0XFF,0XFF,
0XA9,0X7B,0XA3,0X51,0XA1,0X10,0X87,0X11,0X00,0X00,0XFF,0XFF,0XFF,0XFF,0XFF,0XFF,
0XFF,0XFF,0XFF,0XFF,0X00,0X00,0X0A,0X22,0X89,0X19,0XA5,0X00,0X40,0X00,0X69,0X11,
0X67,0X11,0XFF,0XFF,0XFF,0XFF,0XFF,0XFF,0XFF,0XFF,0XFF,0XFF,0XFF,0XFF,0XFF,0XFF,
0XFF,0XFF,0XFF,0XFF,0XFF,0XFF,0XFF,0XFF,0X7A,0XC6,0XFF,0XFF,0XFF,0XFF,0X55,0X9D,
0XF0,0XA4,0X53,0XC6,0X8E,0XB5,0XFF,0XFF,0XFF,0XFF,0X6A,0X7B,0X28,0X4A,0X09,0X3A,
0X83,0X39,0X06,0X2A,0X81,0X00,0X00,0X00,0XFF,0XFF,0XFF,0XFF,0XFF,0XFF,0XFF,0XFF,
0XFF,0XFF,0XFF,0XFF,0XFF,0XFF,0XED,0X42,0X2B,0X09,0X27,0X09,0XCA,0X21,0X28,0X09,
0X00,0X00,0XFF,0XFF,0XFF,0XFF,0XFF,0XFF,0XFF,0XFF,0XFF,0XFF,0XFF,0XFF,0XFF,0XFF,
0XFF,0XFF,0XFF,0XFF,0XFF,0XFF,0XFF,0XFF,0XFF,0XFF,0XFF,0XFF,0X77,0X9D,0XE6,0XA3,
0X84,0XE6,0XFF,0XFF,0XFF,0XFF,0X85,0X8B,0XD7,0XAD,0XCB,0X52,0X0A,0X42,0X00,0X00,
0XFF,0XFF,0XFF,0XFF,0XFF,0XFF,0XFF,0XFF,0XFF,0XFF,0XE3,0X62,0X46,0X94,0XFF,0XFF,
0XFF,0XFF,0XFF,0XFF,0X57,0X7D,0XA3,0X00,0X62,0X00,0XE2,0X39,0X96,0X74,0XA9,0X19,
0XA4,0X21,0XFF,0XFF,0XFF,0XFF,0XFF,0XFF,0XFF,0XFF,0XFF,0XFF,0XFF,0XFF,0XFF,0XFF,
0XFF,0XFF,0XFF,0XFF,0XFF,0XFF,0XFF,0XFF,0XFF,0XFF,0XFF,0XFF,0XF9,0XD6,0XFF,0XFF,
0XFF,0XFF,0X25,0XF6,0X20,0XAB,0XAA,0X3A,0X53,0X74,0XED,0X3A,0X4B,0X3A,0XFF,0XFF,
0XFF,0XFF,0XB6,0X74,0XAE,0X32,0X8D,0X2A,0X69,0X01,0X48,0X53,0X63,0X5A,0X26,0X8C,
0XA8,0X6B,0XF7,0XB5,0X4B,0X32,0XC5,0X52,0XE1,0X7A,0XC3,0X62,0XB6,0X6C,0X0F,0X3B,
0X67,0X32,0X66,0X11,0XFF,0XFF,0XFF,0XFF,0XFF,0XFF,0XFF,0XFF,0XFF,0XFF,0XFF,0XFF,
0XFF,0XFF,0XFF,0XFF,0XFF,0XFF,0XFF,0XFF,0XFF,0XFF,0XFF,0XFF,0XFF,0XFF,0X8F,0X7B,
0XF4,0X84,0XB0,0X5B,0XF6,0X7C,0X8C,0X32,0X5F,0XCF,0XB8,0X9D,0X4F,0X53,0X1D,0XCF,
0X6A,0X32,0X95,0X64,0XD7,0X74,0XAA,0X09,0X0B,0X22,0XD6,0X64,0X02,0X7B,0XA3,0X6A,
0X43,0X52,0X03,0X4A,0X03,0X4A,0XA2,0X31,0XA2,0X00,0X41,0X00,0X63,0X52,0X4F,0X95,
0X6E,0X32,0X86,0X3A,0X67,0X11,0X2C,0X22,0XFF,0XFF,0XFF,0XFF,0X68,0X09,0X47,0X09,
0XFF,0XFF,0X19,0XAE,0XFF,0XFF,0XFF,0XFF,0XFF,0XFF,0X42,0XDD,0XF0,0X8C,0X8B,0X42,
0X6B,0X32,0XE9,0X19,0X4B,0X2A,0X8D,0X32,0X90,0X53,0XB5,0X7C,0X9B,0XC6,0X7B,0XAE,
0X1C,0XC7,0X5D,0XCF,0X69,0X09,0X67,0X09,0X14,0X5C,0X10,0X33,0X4B,0X22,0X02,0X09,
0X25,0X11,0X06,0X11,0XA4,0X00,0XA3,0X08,0X41,0X00,0X40,0X00,0XE1,0X49,0XE7,0X21,
0XD4,0X4B,0XD0,0X4B,0X2B,0X22,0XCA,0X11,0X68,0X09,0X68,0X11,0X89,0X11,0XAA,0X11,
0XFF,0XFF,0XFF,0XFF,0XFF,0XFF,0XA3,0XBC,0XAC,0XC5,0XB7,0X9D,0X0A,0X22,0X86,0X11,
0X65,0X11,0X65,0X11,0X86,0X19,0XCC,0X32,0X4E,0X43,0X4F,0X4B,0X1A,0XA6,0X4F,0X53,
0X91,0X53,0X6D,0X32,0X5C,0XA6,0X69,0X09,0XEA,0X19,0XAD,0X2A,0X0A,0X1A,0X82,0X00,
0X61,0X00,0XC3,0X08,0X05,0X09,0X61,0X00,0X40,0X00,0X60,0X08,0XA1,0X6A,0XC2,0X51,
0X45,0X21,0X48,0X09,0X68,0X09,0X48,0X09,0X68,0X09,0X47,0X09,0X47,0X09,0X26,0X09,
0XFF,0XFF,0XF9,0XDE,0X97,0X95,0XD8,0XA5,0X8C,0X3A,0XEE,0X42,0X6B,0X22,0X86,0X11,
0XE3,0X10,0X24,0X11,0X45,0X11,0XB7,0X95,0XFD,0XBE,0X7B,0XAE,0X6C,0X2A,0X5B,0XA6,
0XFD,0XBE,0XF2,0X53,0X2B,0X22,0X92,0X4B,0X2B,0X1A,0X87,0X11,0XA3,0X08,0X82,0X00,
0X81,0X00,0X41,0X00,0XE4,0X00,0X40,0X00,0X40,0X00,0X40,0X00,0X40,0X00,0X41,0X31,
0XA1,0X39,0X82,0X29,0X27,0X09,0X06,0X09,0X06,0X01,0X05,0X09,0XC4,0X08,0XA3,0X08,
};

const unsigned char gImage_dinosaur[2960] = { /* 0X00,0X10,0X28,0X00,0X25,0X00,0X01,0X1B, */
0XBE,0XF7,0XBE,0XF7,0XBE,0XF7,0XBE,0XF7,0XBE,0XF7,0XBE,0XF7,0XBE,0XF7,0XBE,0XF7,
0XBE,0XF7,0XBE,0XF7,0XBE,0XF7,0XBE,0XF7,0XBE,0XF7,0XBE,0XF7,0XBE,0XF7,0XBE,0XF7,
0XBE,0XF7,0XBE,0XF7,0XBE,0XF7,0XBE,0XF7,0XBE,0XF7,0XBE,0XF7,0XBE,0XF7,0XBE,0XF7,
0XBE,0XF7,0XBE,0XF7,0XBE,0XF7,0XBE,0XF7,0XBE,0XF7,0XBE,0XF7,0XBE,0XF7,0XBE,0XF7,
0XBE,0XF7,0XBE,0XF7,0XBE,0XF7,0XBE,0XF7,0XBE,0XF7,0XBE,0XF7,0XBE,0XF7,0XBE,0XF7,
0XBE,0XF7,0XBE,0XF7,0XBE,0XF7,0XBE,0XF7,0XBE,0XF7,0XBE,0XF7,0XBE,0XF7,0XBE,0XF7,
0XBE,0XF7,0XBE,0XF7,0XBE,0XF7,0XBE,0XF7,0XBE,0XF7,0XBE,0XF7,0XBE,0XF7,0XBE,0XF7,
0XBE,0XF7,0XBE,0XF7,0XBE,0XF7,0XBE,0XF7,0XBE,0XF7,0XBE,0XF7,0XBE,0XF7,0XBE,0XF7,
0XBE,0XF7,0XBE,0XF7,0XBE,0XF7,0XBE,0XF7,0XBE,0XF7,0XBE,0XF7,0XBE,0XF7,0XBE,0XF7,
0XBE,0XF7,0XBE,0XF7,0XBE,0XF7,0XBE,0XF7,0XBE,0XF7,0XBE,0XF7,0XBE,0XF7,0XBE,0XF7,
0XBE,0XF7,0XBE,0XF7,0XBE,0XF7,0XBE,0XF7,0XBE,0XF7,0XBE,0XF7,0XBE,0XF7,0XBE,0XF7,
0XBE,0XF7,0XBE,0XF7,0XBE,0XF7,0XBE,0XF7,0XBE,0XF7,0XBE,0XF7,0XBE,0XF7,0XBE,0XF7,
0XBE,0XF7,0XBE,0XF7,0XBE,0XF7,0XBE,0XF7,0XBE,0XF7,0XBE,0XF7,0XBE,0XF7,0XBE,0XF7,
0XBE,0XF7,0XBE,0XF7,0XBE,0XF7,0XBE,0XF7,0XBE,0XF7,0XBE,0XF7,0XBE,0XF7,0XBE,0XF7,
0XBE,0XF7,0XBE,0XF7,0XBE,0XF7,0XBE,0XF7,0XBE,0XF7,0XBE,0XF7,0XBE,0XF7,0XBE,0XF7,
0XBE,0XF7,0XBE,0XF7,0XBE,0XF7,0XBE,0XF7,0XBE,0XF7,0XBE,0XF7,0XBE,0XF7,0XBE,0XF7,
0XBE,0XF7,0XBE,0XF7,0XBE,0XF7,0XBE,0XF7,0XBE,0XF7,0XBE,0XF7,0XBE,0XF7,0XBE,0XF7,
0XBE,0XF7,0XBE,0XF7,0XBE,0XF7,0XBE,0XF7,0XBE,0XF7,0XBE,0XF7,0XBE,0XF7,0XBE,0XF7,
0XBE,0XF7,0XBE,0XF7,0XBE,0XF7,0XBE,0XF7,0XBE,0XF7,0XBE,0XF7,0XBE,0XF7,0XBE,0XF7,
0XBE,0XF7,0XBE,0XF7,0XBE,0XF7,0XBE,0XF7,0XBE,0XF7,0XBE,0XF7,0XBE,0XF7,0XBE,0XF7,
0XBE,0XF7,0XBE,0XF7,0XBE,0XF7,0XBE,0XF7,0XBE,0XF7,0XBE,0XF7,0XBE,0XF7,0XBE,0XF7,
0XBE,0XF7,0XBE,0XF7,0XBE,0XF7,0XBE,0XF7,0XBE,0XF7,0XBE,0XF7,0XBE,0XF7,0XBE,0XF7,
0XBE,0XF7,0XBE,0XF7,0XBE,0XF7,0XBE,0XF7,0XBE,0XF7,0XBE,0XF7,0XBE,0XF7,0XBE,0XF7,
0XBE,0XF7,0XBE,0XF7,0XBE,0XF7,0XBE,0XF7,0XBE,0XF7,0XBE,0XF7,0XBE,0XF7,0XBE,0XF7,
0XBE,0XF7,0XBE,0XF7,0XBE,0XF7,0XBE,0XF7,0XBE,0XF7,0XBE,0XF7,0XBE,0XF7,0XBE,0XF7,
0XBE,0XF7,0XBE,0XF7,0XBE,0XF7,0XBE,0XF7,0XBE,0XF7,0XBE,0XF7,0XBE,0XF7,0XBE,0XF7,
0XBE,0XF7,0XBE,0XF7,0XBE,0XF7,0XBE,0XF7,0XBE,0XF7,0XBE,0XF7,0XBE,0XF7,0XBE,0XF7,
0XBE,0XF7,0XBE,0XF7,0XBE,0XF7,0XBE,0XF7,0XBE,0XF7,0XBE,0XF7,0XBE,0XF7,0XBE,0XF7,
0XBE,0XF7,0XBE,0XF7,0XBE,0XF7,0XBE,0XF7,0XBE,0XF7,0XBE,0XF7,0XBE,0XF7,0XBE,0XF7,
0XBE,0XF7,0XBE,0XF7,0XBE,0XF7,0XBE,0XF7,0XBE,0XF7,0XBE,0XF7,0XBE,0XF7,0XBE,0XF7,
0XBE,0XF7,0XBE,0XF7,0XBE,0XF7,0XBE,0XF7,0XBE,0XF7,0XBE,0XF7,0XBE,0XF7,0XBE,0XF7,
0XBE,0XF7,0XBE,0XF7,0XBE,0XF7,0XBE,0XF7,0XBE,0XF7,0XBE,0XF7,0XBE,0XF7,0XBE,0XF7,
0XBE,0XF7,0XBE,0XF7,0XBE,0XF7,0XBE,0XF7,0XDF,0XFF,0X7D,0XEF,0X9E,0XF7,0X9E,0XF7,
0X9E,0XF7,0X9E,0XF7,0X9E,0XF7,0X9E,0XF7,0X9E,0XF7,0X9E,0XF7,0X7D,0XEF,0XBE,0XF7,
0XBE,0XF7,0XBE,0XF7,0XBE,0XF7,0XBE,0XF7,0XBE,0XF7,0XBE,0XF7,0XBE,0XF7,0XBE,0XF7,
0XBE,0XF7,0XBE,0XF7,0XBE,0XF7,0XBE,0XF7,0XBE,0XF7,0XBE,0XF7,0XBE,0XF7,0XBE,0XF7,
0XBE,0XF7,0XBE,0XF7,0XBE,0XF7,0XBE,0XF7,0XBE,0XF7,0XBE,0XF7,0XBE,0XF7,0XBE,0XF7,
0XBE,0XF7,0XBE,0XF7,0XBE,0XF7,0XFF,0XFF,0XBE,0XF7,0X28,0X42,0X49,0X4A,0X49,0X4A,
0X49,0X4A,0X49,0X4A,0X49,0X4A,0X49,0X4A,0X49,0X4A,0X49,0X4A,0XBE,0XF7,0XBE,0XF7,
0XBE,0XF7,0XBE,0XF7,0XBE,0XF7,0XBE,0XF7,0XBE,0XF7,0XBE,0XF7,0XBE,0XF7,0XBE,0XF7,
0XBE,0XF7,0XBE,0XF7,0XBE,0XF7,0XBE,0XF7,0XBE,0XF7,0XBE,0XF7,0XBE,0XF7,0XBE,0XF7,
0XBE,0XF7,0XBE,0XF7,0XBE,0XF7,0XBE,0XF7,0XBE,0XF7,0XBE,0XF7,0XBE,0XF7,0XBE,0XF7,
0XBE,0XF7,0XBE,0XF7,0XBE,0XF7,0XBE,0XF7,0X49,0X4A,0X49,0X4A,0XFF,0XFF,0X49,0X4A,
0X49,0X4A,0X49,0X4A,0X49,0X4A,0X49,0X4A,0X49,0X4A,0X49,0X4A,0X49,0X4A,0XBE,0XF7,
0XBE,0XF7,0XBE,0XF7,0XBE,0XF7,0XBE,0XF7,0XBE,0XF7,0XBE,0XF7,0XBE,0XF7,0XBE,0XF7,
0XBE,0XF7,0XBE,0XF7,0XBE,0XF7,0XBE,0XF7,0XBE,0XF7,0XBE,0XF7,0XBE,0XF7,0XBE,0XF7,
0XBE,0XF7,0XBE,0XF7,0XBE,0XF7,0XBE,0XF7,0XBE,0XF7,0XBE,0XF7,0XBE,0XF7,0XBE,0XF7,
0XBE,0XF7,0XBE,0XF7,0XBE,0XF7,0XBE,0XF7,0X49,0X4A,0X49,0X4A,0X69,0X4A,0X49,0X4A,
0X49,0X4A,0X49,0X4A,0X49,0X4A,0X49,0X4A,0X49,0X4A,0X49,0X4A,0X49,0X4A,0XBE,0XF7,
0XBE,0XF7,0XBE,0XF7,0XBE,0XF7,0XBE,0XF7,0XBE,0XF7,0XBE,0XF7,0XBE,0XF7,0XBE,0XF7,
0XBE,0XF7,0XBE,0XF7,0XBE,0XF7,0XBE,0XF7,0XBE,0XF7,0XBE,0XF7,0XBE,0XF7,0XBE,0XF7,
0XBE,0XF7,0XBE,0XF7,0XBE,0XF7,0XBE,0XF7,0XBE,0XF7,0XBE,0XF7,0XBE,0XF7,0XBE,0XF7,
0XBE,0XF7,0XBE,0XF7,0XBE,0XF7,0XBE,0XF7,0X49,0X4A,0X49,0X4A,0X49,0X4A,0X49,0X4A,
0X49,0X4A,0X49,0X4A,0X49,0X4A,0X49,0X4A,0X49,0X4A,0X49,0X4A,0X49,0X4A,0XBE,0XF7,
0XBE,0XF7,0XBE,0XF7,0XBE,0XF7,0XBE,0XF7,0XBE,0XF7,0XBE,0XF7,0XBE,0XF7,0XBE,0XF7,
0XBE,0XF7,0XBE,0XF7,0XBE,0XF7,0XBE,0XF7,0XBE,0XF7,0XBE,0XF7,0XBE,0XF7,0XBE,0XF7,
0XBE,0XF7,0XBE,0XF7,0XBE,0XF7,0XBE,0XF7,0XBE,0XF7,0XBE,0XF7,0XBE,0XF7,0XBE,0XF7,
0XBE,0XF7,0XBE,0XF7,0XBE,0XF7,0XBE,0XF7,0X49,0X4A,0X49,0X4A,0X49,0X4A,0X49,0X4A,
0X49,0X4A,0X49,0X4A,0X49,0X4A,0X49,0X4A,0X49,0X4A,0X49,0X4A,0X49,0X4A,0XBE,0XF7,
0XBE,0XF7,0XBE,0XF7,0XBE,0XF7,0XBE,0XF7,0XBE,0XF7,0XBE,0XF7,0XBE,0XF7,0XBE,0XF7,
0XBE,0XF7,0XBE,0XF7,0XBE,0XF7,0XBE,0XF7,0XBE,0XF7,0XBE,0XF7,0XBE,0XF7,0XBE,0XF7,
0XBE,0XF7,0XBE,0XF7,0XBE,0XF7,0XBE,0XF7,0XBE,0XF7,0XBE,0XF7,0XBE,0XF7,0XBE,0XF7,
0XBE,0XF7,0XBE,0XF7,0XBE,0XF7,0XBE,0XF7,0X49,0X4A,0X49,0X4A,0X49,0X4A,0X49,0X4A,
0X49,0X4A,0X28,0X42,0X49,0X4A,0X49,0X4A,0X49,0X4A,0X49,0X4A,0X49,0X4A,0XBE,0XF7,
0XBE,0XF7,0XBE,0XF7,0XBE,0XF7,0XBE,0XF7,0XBE,0XF7,0XBE,0XF7,0XBE,0XF7,0XBE,0XF7,
0XBE,0XF7,0XBE,0XF7,0XBE,0XF7,0XBE,0XF7,0XBE,0XF7,0XBE,0XF7,0XBE,0XF7,0XBE,0XF7,
0XBE,0XF7,0XBE,0XF7,0XBE,0XF7,0XBE,0XF7,0XBE,0XF7,0XBE,0XF7,0XBE,0XF7,0XBE,0XF7,
0XBE,0XF7,0XBE,0XF7,0XBE,0XF7,0XBE,0XF7,0X49,0X4A,0X49,0X4A,0X49,0X4A,0X49,0X4A,
0X49,0X4A,0XD3,0X9C,0XBE,0XF7,0XBE,0XF7,0XBE,0XF7,0XBE,0XF7,0XDF,0XFF,0XBE,0XF7,
0XBE,0XF7,0XBE,0XF7,0XBE,0XF7,0XBE,0XF7,0XBE,0XF7,0XBE,0XF7,0XBE,0XF7,0XBE,0XF7,
0XBE,0XF7,0XBE,0XF7,0XBE,0XF7,0XBE,0XF7,0XBE,0XF7,0XBE,0XF7,0XBE,0XF7,0XBE,0XF7,
0XBE,0XF7,0XBE,0XF7,0XBE,0XF7,0XBE,0XF7,0XBE,0XF7,0XBE,0XF7,0XBE,0XF7,0XBE,0XF7,
0XBE,0XF7,0XBE,0XF7,0XBE,0XF7,0XBE,0XF7,0X49,0X4A,0X49,0X4A,0X49,0X4A,0X49,0X4A,
0X49,0X4A,0X49,0X4A,0X49,0X4A,0X49,0X4A,0X49,0X4A,0XBE,0XF7,0XBE,0XF7,0XBE,0XF7,
0XBE,0XF7,0XBE,0XF7,0XBE,0XF7,0XBE,0XF7,0XBE,0XF7,0XBE,0XF7,0XBE,0XF7,0XBE,0XF7,
0XBE,0XF7,0XBE,0XF7,0XBE,0XF7,0XBE,0XF7,0XBE,0XF7,0XBE,0XF7,0XBE,0XF7,0XDF,0XFF,
0X49,0X4A,0XFF,0XFF,0XBE,0XF7,0XBE,0XF7,0XBE,0XF7,0XBE,0XF7,0XBE,0XF7,0XBE,0XF7,
0XDF,0XFF,0XBE,0XF7,0X18,0XC6,0X69,0X4A,0X49,0X4A,0X49,0X4A,0X49,0X4A,0X8A,0X52,
0XDF,0XFF,0XDF,0XFF,0XDF,0XFF,0XDF,0XFF,0XDF,0XFF,0XFF,0XFF,0XBE,0XF7,0XBE,0XF7,
0XBE,0XF7,0XBE,0XF7,0XBE,0XF7,0XBE,0XF7,0XBE,0XF7,0XBE,0XF7,0XBE,0XF7,0XBE,0XF7,
0XBE,0XF7,0XBE,0XF7,0XBE,0XF7,0XBE,0XF7,0XBE,0XF7,0XBE,0XF7,0XBE,0XF7,0XBE,0XF7,
0X69,0X4A,0XBE,0XF7,0X9E,0XF7,0XBE,0XF7,0XBE,0XF7,0XBE,0XF7,0XBE,0XF7,0XDF,0XFF,
0XBE,0XF7,0X49,0X4A,0X49,0X4A,0X49,0X4A,0X49,0X4A,0X49,0X4A,0X49,0X4A,0X08,0X42,
0XBE,0XF7,0XBE,0XF7,0X9E,0XF7,0XBE,0XF7,0XBE,0XF7,0XBE,0XF7,0XBE,0XF7,0XBE,0XF7,
0XBE,0XF7,0XBE,0XF7,0XBE,0XF7,0XBE,0XF7,0XBE,0XF7,0XBE,0XF7,0XBE,0XF7,0XBE,0XF7,
0XBE,0XF7,0XBE,0XF7,0XBE,0XF7,0XBE,0XF7,0XBE,0XF7,0XBE,0XF7,0XBE,0XF7,0XBE,0XF7,
0X28,0X42,0XD3,0X9C,0XBE,0XF7,0XBE,0XF7,0XBE,0XF7,0XBE,0XF7,0XBE,0XF7,0XD3,0X9C,
0XF3,0X9C,0X49,0X4A,0X49,0X4A,0X49,0X4A,0X49,0X4A,0X49,0X4A,0X49,0X4A,0X49,0X4A,
0X14,0XA5,0XF3,0X9C,0XF3,0X9C,0XBE,0XF7,0XBE,0XF7,0XBE,0XF7,0XBE,0XF7,0XBE,0XF7,
0XBE,0XF7,0XBE,0XF7,0XBE,0XF7,0XBE,0XF7,0XBE,0XF7,0XBE,0XF7,0XBE,0XF7,0XBE,0XF7,
0XBE,0XF7,0XBE,0XF7,0XBE,0XF7,0XBE,0XF7,0XBE,0XF7,0XBE,0XF7,0XBE,0XF7,0XBE,0XF7,
0X49,0X4A,0X49,0X4A,0X3C,0XE7,0X5D,0XEF,0XBE,0XF7,0XBE,0XF7,0XDF,0XFF,0X49,0X4A,
0X49,0X4A,0X49,0X4A,0X49,0X4A,0X49,0X4A,0X49,0X4A,0X49,0X4A,0X49,0X4A,0X8A,0X52,
0X69,0X4A,0X8A,0X52,0X49,0X4A,0XBE,0XF7,0XBE,0XF7,0XBE,0XF7,0XBE,0XF7,0XBE,0XF7,
0XBE,0XF7,0XBE,0XF7,0XBE,0XF7,0XBE,0XF7,0XBE,0XF7,0XBE,0XF7,0XBE,0XF7,0XBE,0XF7,
0XBE,0XF7,0XBE,0XF7,0XBE,0XF7,0XBE,0XF7,0XBE,0XF7,0XBE,0XF7,0XBE,0XF7,0XBE,0XF7,
0X49,0X4A,0X49,0X4A,0X49,0X4A,0X8A,0X52,0XBE,0XF7,0XBE,0XF7,0X49,0X4A,0X49,0X4A,
0X49,0X4A,0X49,0X4A,0X49,0X4A,0X49,0X4A,0X49,0X4A,0X49,0X4A,0X49,0X4A,0X28,0X42,
0XBE,0XF7,0X14,0XA5,0X8A,0X52,0XBE,0XF7,0XBE,0XF7,0XBE,0XF7,0XBE,0XF7,0XBE,0XF7,
0XBE,0XF7,0XBE,0XF7,0XBE,0XF7,0XBE,0XF7,0XBE,0XF7,0XBE,0XF7,0XBE,0XF7,0XBE,0XF7,
0XBE,0XF7,0XBE,0XF7,0XBE,0XF7,0XBE,0XF7,0XBE,0XF7,0XBE,0XF7,0XBE,0XF7,0XBE,0XF7,
0X49,0X4A,0X49,0X4A,0X49,0X4A,0X49,0X4A,0X49,0X4A,0X49,0X4A,0X49,0X4A,0X49,0X4A,
0X49,0X4A,0X49,0X4A,0X49,0X4A,0X49,0X4A,0X49,0X4A,0X49,0X4A,0X49,0X4A,0X28,0X42,
0XBE,0XF7,0XBE,0XF7,0XBE,0XF7,0XBE,0XF7,0XBE,0XF7,0XBE,0XF7,0XBE,0XF7,0XBE,0XF7,
0XBE,0XF7,0XBE,0XF7,0XBE,0XF7,0XBE,0XF7,0XBE,0XF7,0XBE,0XF7,0XBE,0XF7,0XBE,0XF7,
0XBE,0XF7,0XBE,0XF7,0XBE,0XF7,0XBE,0XF7,0XBE,0XF7,0XBE,0XF7,0XBE,0XF7,0XBE,0XF7,
0X49,0X4A,0X49,0X4A,0X49,0X4A,0X49,0X4A,0X49,0X4A,0X49,0X4A,0X49,0X4A,0X49,0X4A,
0X49,0X4A,0X49,0X4A,0X49,0X4A,0X49,0X4A,0X49,0X4A,0X49,0X4A,0X49,0X4A,0X28,0X42,
0XBE,0XF7,0XBE,0XF7,0XBE,0XF7,0XBE,0XF7,0XBE,0XF7,0XBE,0XF7,0XBE,0XF7,0XBE,0XF7,
0XBE,0XF7,0XBE,0XF7,0XBE,0XF7,0XBE,0XF7,0XBE,0XF7,0XBE,0XF7,0XBE,0XF7,0XBE,0XF7,
0XBE,0XF7,0XBE,0XF7,0XBE,0XF7,0XBE,0XF7,0XBE,0XF7,0XBE,0XF7,0XBE,0XF7,0XFF,0XFF,
0XBE,0XF7,0X28,0X42,0X49,0X4A,0X49,0X4A,0X49,0X4A,0X49,0X4A,0X49,0X4A,0X49,0X4A,
0X49,0X4A,0X49,0X4A,0X49,0X4A,0X49,0X4A,0X49,0X4A,0X49,0X4A,0X49,0X4A,0X28,0X42,
0XDB,0XDE,0XBE,0XF7,0XBE,0XF7,0XBE,0XF7,0XBE,0XF7,0XBE,0XF7,0XBE,0XF7,0XBE,0XF7,
0XBE,0XF7,0XBE,0XF7,0XBE,0XF7,0XBE,0XF7,0XBE,0XF7,0XBE,0XF7,0XBE,0XF7,0XBE,0XF7,
0XBE,0XF7,0XBE,0XF7,0XBE,0XF7,0XBE,0XF7,0XBE,0XF7,0XBE,0XF7,0XBE,0XF7,0XBE,0XF7,
0X9E,0XF7,0XDF,0XFF,0X49,0X4A,0X28,0X42,0X49,0X4A,0X49,0X4A,0X49,0X4A,0X49,0X4A,
0X49,0X4A,0X49,0X4A,0X49,0X4A,0X49,0X4A,0X49,0X4A,0X49,0X4A,0X8A,0X52,0XBE,0XF7,
0XBE,0XF7,0XBE,0XF7,0XBE,0XF7,0XBE,0XF7,0XBE,0XF7,0XBE,0XF7,0XBE,0XF7,0XBE,0XF7,
0XBE,0XF7,0XBE,0XF7,0XBE,0XF7,0XBE,0XF7,0XBE,0XF7,0XBE,0XF7,0XBE,0XF7,0XBE,0XF7,
0XBE,0XF7,0XBE,0XF7,0XBE,0XF7,0XBE,0XF7,0XBE,0XF7,0XBE,0XF7,0XBE,0XF7,0XBE,0XF7,
0X9E,0XF7,0X9E,0XF7,0X55,0XAD,0X18,0XC6,0X49,0X4A,0X49,0X4A,0X49,0X4A,0X49,0X4A,
0X49,0X4A,0X49,0X4A,0X49,0X4A,0X49,0X4A,0X49,0X4A,0X49,0X4A,0XF7,0XBD,0XBE,0XF7,
0XBE,0XF7,0XBE,0XF7,0XBE,0XF7,0XBE,0XF7,0XBE,0XF7,0XBE,0XF7,0XBE,0XF7,0XBE,0XF7,
0XBE,0XF7,0XBE,0XF7,0XBE,0XF7,0XBE,0XF7,0XBE,0XF7,0XBE,0XF7,0XBE,0XF7,0XBE,0XF7,
0XBE,0XF7,0XBE,0XF7,0XBE,0XF7,0XBE,0XF7,0XBE,0XF7,0XBE,0XF7,0XBE,0XF7,0XBE,0XF7,
0XBE,0XF7,0XBE,0XF7,0XBE,0XF7,0XFB,0XDE,0X49,0X4A,0X49,0X4A,0X49,0X4A,0X49,0X4A,
0X49,0X4A,0X49,0X4A,0X49,0X4A,0X49,0X4A,0X08,0X42,0X69,0X4A,0XDF,0XFF,0XBE,0XF7,
0XBE,0XF7,0XBE,0XF7,0XBE,0XF7,0XBE,0XF7,0XBE,0XF7,0XBE,0XF7,0XBE,0XF7,0XBE,0XF7,
0XBE,0XF7,0XBE,0XF7,0XBE,0XF7,0XBE,0XF7,0XBE,0XF7,0XBE,0XF7,0XBE,0XF7,0XBE,0XF7,
0XBE,0XF7,0XBE,0XF7,0XBE,0XF7,0XBE,0XF7,0XBE,0XF7,0XBE,0XF7,0XBE,0XF7,0XBE,0XF7,
0XBE,0XF7,0XBE,0XF7,0XBE,0XF7,0XBE,0XF7,0XBE,0XF7,0X28,0X42,0X49,0X4A,0X49,0X4A,
0X28,0X42,0X08,0X42,0X69,0X4A,0X49,0X4A,0X49,0X4A,0XDF,0XFF,0XBE,0XF7,0XBE,0XF7,
0XBE,0XF7,0XBE,0XF7,0XBE,0XF7,0XBE,0XF7,0XBE,0XF7,0XBE,0XF7,0XBE,0XF7,0XBE,0XF7,
0XBE,0XF7,0XBE,0XF7,0XBE,0XF7,0XBE,0XF7,0XBE,0XF7,0XBE,0XF7,0XBE,0XF7,0XBE,0XF7,
0XBE,0XF7,0XBE,0XF7,0XBE,0XF7,0XBE,0XF7,0XBE,0XF7,0XBE,0XF7,0XBE,0XF7,0XBE,0XF7,
0XBE,0XF7,0XBE,0XF7,0XBE,0XF7,0XBE,0XF7,0XBE,0XF7,0XBE,0XF7,0X49,0X4A,0X49,0X4A,
0X69,0X4A,0X7D,0XEF,0X18,0XC6,0X69,0X4A,0X49,0X4A,0XDF,0XFF,0XBE,0XF7,0XBE,0XF7,
0XBE,0XF7,0XBE,0XF7,0XBE,0XF7,0XBE,0XF7,0XBE,0XF7,0XBE,0XF7,0XBE,0XF7,0XBE,0XF7,
0XBE,0XF7,0XBE,0XF7,0XBE,0XF7,0XBE,0XF7,0XBE,0XF7,0XBE,0XF7,0XBE,0XF7,0XBE,0XF7,
0XBE,0XF7,0XBE,0XF7,0XBE,0XF7,0XBE,0XF7,0XBE,0XF7,0XBE,0XF7,0XBE,0XF7,0XBE,0XF7,
0XBE,0XF7,0XBE,0XF7,0XBE,0XF7,0XBE,0XF7,0XBE,0XF7,0XBE,0XF7,0X49,0X4A,0X49,0X4A,
0XBE,0XF7,0XBE,0XF7,0XBE,0XF7,0XBE,0XF7,0X49,0X4A,0XDF,0XFF,0XBE,0XF7,0XBE,0XF7,
0XBE,0XF7,0XBE,0XF7,0XBE,0XF7,0XBE,0XF7,0XBE,0XF7,0XBE,0XF7,0XBE,0XF7,0XBE,0XF7,
0XBE,0XF7,0XBE,0XF7,0XBE,0XF7,0XBE,0XF7,0XBE,0XF7,0XBE,0XF7,0XBE,0XF7,0XBE,0XF7,
0XBE,0XF7,0XBE,0XF7,0XBE,0XF7,0XBE,0XF7,0XBE,0XF7,0XBE,0XF7,0XBE,0XF7,0XBE,0XF7,
0XBE,0XF7,0XBE,0XF7,0XBE,0XF7,0XBE,0XF7,0XBE,0XF7,0XBE,0XF7,0X49,0X4A,0XBE,0XF7,
0XBE,0XF7,0XBE,0XF7,0XBE,0XF7,0XBE,0XF7,0X49,0X4A,0XDF,0XFF,0XBE,0XF7,0XBE,0XF7,
0XBE,0XF7,0XBE,0XF7,0XBE,0XF7,0XBE,0XF7,0XBE,0XF7,0XBE,0XF7,0XBE,0XF7,0XBE,0XF7,
0XBE,0XF7,0XBE,0XF7,0XBE,0XF7,0XBE,0XF7,0XBE,0XF7,0XBE,0XF7,0XBE,0XF7,0XBE,0XF7,
0XBE,0XF7,0XBE,0XF7,0XBE,0XF7,0XBE,0XF7,0XBE,0XF7,0XBE,0XF7,0XBE,0XF7,0XBE,0XF7,
0XBE,0XF7,0XBE,0XF7,0XBE,0XF7,0XBE,0XF7,0XBE,0XF7,0XBE,0XF7,0X49,0X4A,0XE7,0X39,
0XBE,0XF7,0XBE,0XF7,0XBE,0XF7,0XBE,0XF7,0X08,0X42,0X69,0X4A,0XDF,0XFF,0XBE,0XF7,
0XBE,0XF7,0XBE,0XF7,0XBE,0XF7,0XBE,0XF7,0XBE,0XF7,0XBE,0XF7,0XBE,0XF7,0XBE,0XF7,
0XBE,0XF7,0XBE,0XF7,0XBE,0XF7,0XBE,0XF7,0XBE,0XF7,0XBE,0XF7,0XBE,0XF7,0XBE,0XF7,
0XBE,0XF7,0XBE,0XF7,0XBE,0XF7,0XBE,0XF7,0XBE,0XF7,0XBE,0XF7,0XBE,0XF7,0XBE,0XF7,
0XBE,0XF7,0XBE,0XF7,0XBE,0XF7,0XBE,0XF7,0XBE,0XF7,0XBE,0XF7,0XBE,0XF7,0XBE,0XF7,
0XBE,0XF7,0XBE,0XF7,0XBE,0XF7,0XBE,0XF7,0XBE,0XF7,0XBE,0XF7,0XBE,0XF7,0XBE,0XF7,
0XBE,0XF7,0XBE,0XF7,0XBE,0XF7,0XBE,0XF7,0XBE,0XF7,0XBE,0XF7,0XBE,0XF7,0XBE,0XF7,
0XBE,0XF7,0XBE,0XF7,0XBE,0XF7,0XBE,0XF7,0XBE,0XF7,0XBE,0XF7,0XBE,0XF7,0XBE,0XF7,
0XBE,0XF7,0XBE,0XF7,0XBE,0XF7,0XBE,0XF7,0XBE,0XF7,0XBE,0XF7,0XBE,0XF7,0XBE,0XF7,
0XBE,0XF7,0XBE,0XF7,0XBE,0XF7,0XBE,0XF7,0XBE,0XF7,0XBE,0XF7,0XBE,0XF7,0XBE,0XF7,
0XBE,0XF7,0XBE,0XF7,0XBE,0XF7,0XBE,0XF7,0XBE,0XF7,0XBE,0XF7,0XBE,0XF7,0XBE,0XF7,
0XBE,0XF7,0XBE,0XF7,0XBE,0XF7,0XBE,0XF7,0XBE,0XF7,0XBE,0XF7,0XBE,0XF7,0XBE,0XF7,
0XBE,0XF7,0XBE,0XF7,0XBE,0XF7,0XBE,0XF7,0XBE,0XF7,0XBE,0XF7,0XBE,0XF7,0XBE,0XF7,
0XBE,0XF7,0XBE,0XF7,0XBE,0XF7,0XBE,0XF7,0XBE,0XF7,0XBE,0XF7,0XBE,0XF7,0XBE,0XF7,
0XBE,0XF7,0XBE,0XF7,0XBE,0XF7,0XBE,0XF7,0XBE,0XF7,0XBE,0XF7,0XBE,0XF7,0XBE,0XF7,
0XBE,0XF7,0XBE,0XF7,0XBE,0XF7,0XBE,0XF7,0XBE,0XF7,0XBE,0XF7,0XBE,0XF7,0XBE,0XF7,
0XBE,0XF7,0XBE,0XF7,0XBE,0XF7,0XBE,0XF7,0XBE,0XF7,0XBE,0XF7,0XBE,0XF7,0XBE,0XF7,
0XBE,0XF7,0XBE,0XF7,0XBE,0XF7,0XBE,0XF7,0XBE,0XF7,0XBE,0XF7,0XBE,0XF7,0XBE,0XF7,
0XBE,0XF7,0XBE,0XF7,0XBE,0XF7,0XBE,0XF7,0XBE,0XF7,0XBE,0XF7,0XBE,0XF7,0XBE,0XF7,
0XBE,0XF7,0XBE,0XF7,0XBE,0XF7,0XBE,0XF7,0XBE,0XF7,0XBE,0XF7,0XBE,0XF7,0XBE,0XF7,
0XBE,0XF7,0XBE,0XF7,0XBE,0XF7,0XBE,0XF7,0XBE,0XF7,0XBE,0XF7,0XBE,0XF7,0XBE,0XF7,
0XBE,0XF7,0XBE,0XF7,0XBE,0XF7,0XBE,0XF7,0XBE,0XF7,0XBE,0XF7,0XBE,0XF7,0XBE,0XF7,
0XBE,0XF7,0XBE,0XF7,0XBE,0XF7,0XBE,0XF7,0XBE,0XF7,0XBE,0XF7,0XBE,0XF7,0XBE,0XF7,
0XBE,0XF7,0XBE,0XF7,0XBE,0XF7,0XBE,0XF7,0XBE,0XF7,0XBE,0XF7,0XBE,0XF7,0XBE,0XF7,
0XBE,0XF7,0XBE,0XF7,0XBE,0XF7,0XBE,0XF7,0XBE,0XF7,0XBE,0XF7,0XBE,0XF7,0XBE,0XF7,
0XBE,0XF7,0XBE,0XF7,0XBE,0XF7,0XBE,0XF7,0XBE,0XF7,0XBE,0XF7,0XBE,0XF7,0XBE,0XF7,
0XBE,0XF7,0XBE,0XF7,0XBE,0XF7,0XBE,0XF7,0XBE,0XF7,0XBE,0XF7,0XBE,0XF7,0XBE,0XF7,
0XBE,0XF7,0XBE,0XF7,0XBE,0XF7,0XBE,0XF7,0XBE,0XF7,0XBE,0XF7,0XBE,0XF7,0XBE,0XF7,
0XBE,0XF7,0XBE,0XF7,0XBE,0XF7,0XBE,0XF7,0XBE,0XF7,0XBE,0XF7,0XBE,0XF7,0XBE,0XF7,
0XBE,0XF7,0XBE,0XF7,0XBE,0XF7,0XBE,0XF7,0XBE,0XF7,0XBE,0XF7,0XBE,0XF7,0XBE,0XF7,
0XBE,0XF7,0XBE,0XF7,0XBE,0XF7,0XBE,0XF7,0XBE,0XF7,0XBE,0XF7,0XBE,0XF7,0XBE,0XF7,
0XBE,0XF7,0XBE,0XF7,0XBE,0XF7,0XBE,0XF7,0XBE,0XF7,0XBE,0XF7,0XBE,0XF7,0XBE,0XF7,
0XBE,0XF7,0XBE,0XF7,0XBE,0XF7,0XBE,0XF7,0XBE,0XF7,0XBE,0XF7,0XBE,0XF7,0XBE,0XF7,
};

const unsigned char gImage_dinosaur_jump[2880] = { /* 0X00,0X10,0X24,0X00,0X28,0X00,0X01,0X1B, */
0XBE,0XF7,0XBE,0XF7,0XBE,0XF7,0XBE,0XF7,0XBE,0XF7,0XBE,0XF7,0XBE,0XF7,0XBE,0XF7,
0XBE,0XF7,0XBE,0XF7,0XBE,0XF7,0XBE,0XF7,0XBE,0XF7,0XBE,0XF7,0XBE,0XF7,0XBE,0XF7,
0XBE,0XF7,0XBE,0XF7,0XBE,0XF7,0XBE,0XF7,0XBE,0XF7,0XBE,0XF7,0XBE,0XF7,0XBE,0XF7,
0XBE,0XF7,0XBE,0XF7,0XBE,0XF7,0XBE,0XF7,0XBE,0XF7,0XBE,0XF7,0XBE,0XF7,0XBE,0XF7,
0XBE,0XF7,0XBE,0XF7,0XBE,0XF7,0XBE,0XF7,0XBE,0XF7,0XBE,0XF7,0XBE,0XF7,0XBE,0XF7,
0XBE,0XF7,0XBE,0XF7,0XBE,0XF7,0XBE,0XF7,0XBE,0XF7,0XBE,0XF7,0XBE,0XF7,0XBE,0XF7,
0XBE,0XF7,0XBE,0XF7,0XBE,0XF7,0XBE,0XF7,0XBE,0XF7,0XBE,0XF7,0XBE,0XF7,0XBE,0XF7,
0XBE,0XF7,0XBE,0XF7,0XBE,0XF7,0XBE,0XF7,0XBE,0XF7,0XBE,0XF7,0XBE,0XF7,0XBE,0XF7,
0XBE,0XF7,0XBE,0XF7,0XBE,0XF7,0XBE,0XF7,0XBE,0XF7,0XBE,0XF7,0XBE,0XF7,0XBE,0XF7,
0XBE,0XF7,0XBE,0XF7,0XBE,0XF7,0XBE,0XF7,0XBE,0XF7,0XBE,0XF7,0XBE,0XF7,0XBE,0XF7,
0XBE,0XF7,0XBE,0XF7,0XBE,0XF7,0XBE,0XF7,0XBE,0XF7,0XBE,0XF7,0XBE,0XF7,0XBE,0XF7,
0XBE,0XF7,0XBE,0XF7,0XBE,0XF7,0XBE,0XF7,0XBE,0XF7,0XBE,0XF7,0XBE,0XF7,0XBE,0XF7,
0XBE,0XF7,0XBE,0XF7,0XBE,0XF7,0XBE,0XF7,0XBE,0XF7,0XBE,0XF7,0XBE,0XF7,0XBE,0XF7,
0XBE,0XF7,0XBE,0XF7,0XBE,0XF7,0XBE,0XF7,0XBE,0XF7,0XBE,0XF7,0XBE,0XF7,0XBE,0XF7,
0XBE,0XF7,0XBE,0XF7,0XBE,0XF7,0XBE,0XF7,0XBE,0XF7,0XBE,0XF7,0XBE,0XF7,0XBE,0XF7,
0XBE,0XF7,0XBE,0XF7,0XBE,0XF7,0XBE,0XF7,0XBE,0XF7,0XBE,0XF7,0XBE,0XF7,0XBE,0XF7,
0XBE,0XF7,0XBE,0XF7,0XBE,0XF7,0XBE,0XF7,0XBE,0XF7,0XBE,0XF7,0XBE,0XF7,0XBE,0XF7,
0XBE,0XF7,0XBE,0XF7,0XBE,0XF7,0XBE,0XF7,0XBE,0XF7,0XBE,0XF7,0XBE,0XF7,0XBE,0XF7,
0XBE,0XF7,0XBE,0XF7,0XBE,0XF7,0XBE,0XF7,0XBE,0XF7,0XBE,0XF7,0XBE,0XF7,0XBE,0XF7,
0XBE,0XF7,0XBE,0XF7,0XBE,0XF7,0XBE,0XF7,0XBE,0XF7,0XBE,0XF7,0XBE,0XF7,0XBE,0XF7,
0XBE,0XF7,0XBE,0XF7,0XBE,0XF7,0XBE,0XF7,0XBE,0XF7,0XBE,0XF7,0XBE,0XF7,0XBE,0XF7,
0XBE,0XF7,0XBE,0XF7,0XBE,0XF7,0XBE,0XF7,0XBE,0XF7,0XBE,0XF7,0XBE,0XF7,0XBE,0XF7,
0XBE,0XF7,0XBE,0XF7,0XBE,0XF7,0XBE,0XF7,0XBE,0XF7,0XBE,0XF7,0XBE,0XF7,0XBE,0XF7,
0XBE,0XF7,0XBE,0XF7,0XBE,0XF7,0XBE,0XF7,0XBE,0XF7,0XBE,0XF7,0XBE,0XF7,0XBE,0XF7,
0XBE,0XF7,0XBE,0XF7,0XBE,0XF7,0XBE,0XF7,0XBE,0XF7,0XBE,0XF7,0XBE,0XF7,0XBE,0XF7,
0XBE,0XF7,0XBE,0XF7,0XBE,0XF7,0XBE,0XF7,0XBE,0XF7,0XBE,0XF7,0XBE,0XF7,0XBE,0XF7,
0XBE,0XF7,0XBE,0XF7,0XBE,0XF7,0XBE,0XF7,0XBE,0XF7,0XBE,0XF7,0XBE,0XF7,0XBE,0XF7,
0XBE,0XF7,0XBE,0XF7,0XBE,0XF7,0XBE,0XF7,0XBE,0XF7,0XBE,0XF7,0XBE,0XF7,0XBE,0XF7,
0XBE,0XF7,0XBE,0XF7,0XBE,0XF7,0XBE,0XF7,0XBE,0XF7,0XBE,0XF7,0XBE,0XF7,0XBE,0XF7,
0XBE,0XF7,0XBE,0XF7,0XBE,0XF7,0XBE,0XF7,0XBE,0XF7,0XBE,0XF7,0XBE,0XF7,0XBE,0XF7,
0XBE,0XF7,0XBE,0XF7,0XBE,0XF7,0XBE,0XF7,0XBE,0XF7,0XBE,0XF7,0XBE,0XF7,0XBE,0XF7,
0XBE,0XF7,0XBE,0XF7,0XBE,0XF7,0XBE,0XF7,0XBE,0XF7,0XBE,0XF7,0XBE,0XF7,0XBE,0XF7,
0XBE,0XF7,0XBE,0XF7,0XBE,0XF7,0XBE,0XF7,0XBE,0XF7,0XBE,0XF7,0XBE,0XF7,0XBE,0XF7,
0XBE,0XF7,0XBE,0XF7,0XBE,0XF7,0XBE,0XF7,0XBE,0XF7,0XBE,0XF7,0XBE,0XF7,0XBE,0XF7,
0XBE,0XF7,0XBE,0XF7,0XBE,0XF7,0XBE,0XF7,0XBE,0XF7,0XBE,0XF7,0XBE,0XF7,0XBE,0XF7,
0XBE,0XF7,0XBE,0XF7,0XBE,0XF7,0XBE,0XF7,0XBE,0XF7,0XBE,0XF7,0XBE,0XF7,0XBE,0XF7,
0XBE,0XF7,0XBE,0XF7,0XBE,0XF7,0XBE,0XF7,0XBE,0XF7,0XBE,0XF7,0XBE,0XF7,0XBE,0XF7,
0XBE,0XF7,0XBE,0XF7,0XBE,0XF7,0XBE,0XF7,0XBE,0XF7,0XBE,0XF7,0XBE,0XF7,0XBE,0XF7,
0XBE,0XF7,0XBE,0XF7,0XBE,0XF7,0XBE,0XF7,0XBE,0XF7,0XBE,0XF7,0XBE,0XF7,0XBE,0XF7,
0XBE,0XF7,0XBE,0XF7,0XBE,0XF7,0XBE,0XF7,0XBE,0XF7,0XBE,0XF7,0XBE,0XF7,0XBE,0XF7,
0XBE,0XF7,0XBE,0XF7,0XBE,0XF7,0XBE,0XF7,0XBE,0XF7,0XBE,0XF7,0XBE,0XF7,0XBE,0XF7,
0XBE,0XF7,0XFF,0XFF,0XBE,0XF7,0X28,0X42,0X49,0X4A,0X49,0X4A,0X49,0X4A,0X49,0X4A,
0XDF,0XFF,0XBE,0XF7,0XBE,0XF7,0XBE,0XF7,0XBE,0XF7,0XBE,0XF7,0XBE,0XF7,0XBE,0XF7,
0XBE,0XF7,0XBE,0XF7,0XBE,0XF7,0XBE,0XF7,0XBE,0XF7,0XBE,0XF7,0XBE,0XF7,0XBE,0XF7,
0XBE,0XF7,0XBE,0XF7,0XBE,0XF7,0XBE,0XF7,0XBE,0XF7,0XBE,0XF7,0XBE,0XF7,0XBE,0XF7,
0XBE,0XF7,0XBE,0XF7,0XBE,0XF7,0XBE,0XF7,0XBE,0XF7,0XBE,0XF7,0X49,0X4A,0X49,0X4A,
0X49,0X4A,0X49,0X4A,0X49,0X4A,0X49,0X4A,0XBE,0XF7,0XBE,0XF7,0X9E,0XF7,0X9E,0XF7,
0XBE,0XF7,0XBE,0XF7,0XBE,0XF7,0XBE,0XF7,0XBE,0XF7,0XBE,0XF7,0XBE,0XF7,0XBE,0XF7,
0XBE,0XF7,0XBE,0XF7,0XBE,0XF7,0XBE,0XF7,0XBE,0XF7,0XBE,0XF7,0XBE,0XF7,0XBE,0XF7,
0XBE,0XF7,0XBE,0XF7,0XBE,0XF7,0XBE,0XF7,0XBE,0XF7,0XBE,0XF7,0XBE,0XF7,0XBE,0XF7,
0XBE,0XF7,0XBE,0XF7,0X49,0X4A,0X49,0X4A,0X49,0X4A,0X49,0X4A,0X49,0X4A,0X49,0X4A,
0XBE,0XF7,0X08,0X42,0X30,0X84,0XBE,0XF7,0XBE,0XF7,0XBE,0XF7,0XBE,0XF7,0XBE,0XF7,
0XBE,0XF7,0XBE,0XF7,0XBE,0XF7,0XBE,0XF7,0XBE,0XF7,0XBE,0XF7,0XBE,0XF7,0XBE,0XF7,
0XBE,0XF7,0XBE,0XF7,0XBE,0XF7,0XBE,0XF7,0XBE,0XF7,0XBE,0XF7,0XBE,0XF7,0XBE,0XF7,
0XBE,0XF7,0XBE,0XF7,0XBE,0XF7,0XBE,0XF7,0XBE,0XF7,0XBE,0XF7,0X49,0X4A,0X49,0X4A,
0X49,0X4A,0X49,0X4A,0X49,0X4A,0X49,0X4A,0XBE,0XF7,0X08,0X42,0X30,0X84,0XBE,0XF7,
0XBE,0XF7,0XBE,0XF7,0XBE,0XF7,0XBE,0XF7,0XBE,0XF7,0XBE,0XF7,0XBE,0XF7,0XBE,0XF7,
0XBE,0XF7,0XBE,0XF7,0XBE,0XF7,0XBE,0XF7,0XBE,0XF7,0XBE,0XF7,0XBE,0XF7,0XBE,0XF7,
0XBE,0XF7,0XBE,0XF7,0XBE,0XF7,0XBE,0XF7,0XBE,0XF7,0XBE,0XF7,0XBE,0XF7,0XBE,0XF7,
0XBE,0XF7,0XBE,0XF7,0X49,0X4A,0X49,0X4A,0X49,0X4A,0X49,0X4A,0X49,0X4A,0X49,0X4A,
0XBE,0XF7,0X08,0X42,0X30,0X84,0XBE,0XF7,0X9E,0XEF,0XB2,0X94,0XD2,0X94,0XBE,0XF7,
0XBE,0XF7,0XBE,0XF7,0XBE,0XF7,0XBE,0XF7,0XBE,0XF7,0XBE,0XF7,0XBE,0XF7,0XBE,0XF7,
0XBE,0XF7,0XBE,0XF7,0XBE,0XF7,0XBE,0XF7,0XBE,0XF7,0XBE,0XF7,0XBE,0XF7,0XBE,0XF7,
0XBE,0XF7,0XBE,0XF7,0XBE,0XF7,0XBE,0XF7,0XBE,0XF7,0XBE,0XF7,0X49,0X4A,0X49,0X4A,
0X49,0X4A,0X49,0X4A,0X49,0X4A,0X49,0X4A,0X3C,0XE7,0X48,0X42,0X30,0X84,0XBE,0XF7,
0X5D,0XEF,0X49,0X4A,0XAA,0X52,0XBE,0XF7,0XBE,0XF7,0XBE,0XF7,0XBE,0XF7,0XBE,0XF7,
0XBE,0XF7,0XBE,0XF7,0XBE,0XF7,0XBE,0XF7,0XBE,0XF7,0XBE,0XF7,0XBE,0XF7,0XBE,0XF7,
0XBE,0XF7,0XBE,0XF7,0XBE,0XF7,0XBE,0XF7,0XBE,0XF7,0XBE,0XF7,0XBE,0XF7,0XBE,0XF7,
0XBE,0XF7,0XBE,0XF7,0X49,0X4A,0X49,0X4A,0X49,0X4A,0X49,0X4A,0X49,0X4A,0X49,0X4A,
0X28,0X42,0X28,0X42,0X30,0X84,0XBE,0XF7,0X5D,0XEF,0XAA,0X52,0XBE,0XF7,0XBE,0XF7,
0XBE,0XF7,0XBE,0XF7,0XBE,0XF7,0XBE,0XF7,0XBE,0XF7,0XBE,0XF7,0XBE,0XF7,0XBE,0XF7,
0XBE,0XF7,0XBE,0XF7,0XBE,0XF7,0XBE,0XF7,0XBE,0XF7,0XBE,0XF7,0XBE,0XF7,0XBE,0XF7,
0XBE,0XF7,0XBE,0XF7,0XBE,0XF7,0XBE,0XF7,0XBE,0XF7,0XBE,0XF7,0X49,0X4A,0X49,0X4A,
0X49,0X4A,0X49,0X4A,0X49,0X4A,0X49,0X4A,0X49,0X4A,0X49,0X4A,0X28,0X42,0X69,0X4A,
0X69,0X4A,0X49,0X4A,0X69,0X4A,0X69,0X4A,0X69,0X4A,0X08,0X42,0XBE,0XF7,0XBE,0XF7,
0XBE,0XF7,0XBE,0XF7,0XBE,0XF7,0XBE,0XF7,0XBE,0XF7,0XBE,0XF7,0XBE,0XF7,0XBE,0XF7,
0XBE,0XF7,0XBE,0XF7,0XBE,0XF7,0XBE,0XF7,0XBE,0XF7,0XBE,0XF7,0XBE,0XF7,0XBE,0XF7,
0XBE,0XF7,0XBE,0XF7,0X49,0X4A,0X49,0X4A,0XFF,0XFF,0X49,0X4A,0X49,0X4A,0X49,0X4A,
0X49,0X4A,0X49,0X4A,0X49,0X4A,0X49,0X4A,0X49,0X4A,0X49,0X4A,0X49,0X4A,0X49,0X4A,
0X49,0X4A,0X49,0X4A,0X28,0X42,0X1C,0XE7,0XBE,0XF7,0XBE,0XF7,0XBE,0XF7,0XBE,0XF7,
0XBE,0XF7,0X7D,0XEF,0XBE,0XF7,0XBE,0XF7,0XBE,0XF7,0XBE,0XF7,0XBE,0XF7,0XBE,0XF7,
0XBE,0XF7,0XBE,0XF7,0XBE,0XF7,0XBE,0XF7,0XBE,0XF7,0X9E,0XF7,0X69,0X4A,0X28,0X42,
0X49,0X4A,0X49,0X4A,0X49,0X4A,0X49,0X4A,0X49,0X4A,0X49,0X4A,0X49,0X4A,0X49,0X4A,
0X49,0X4A,0X49,0X4A,0X49,0X4A,0X49,0X4A,0X49,0X4A,0X49,0X4A,0X49,0X4A,0X69,0X4A,
0X6D,0X6B,0XBE,0XF7,0XBE,0XF7,0XBE,0XF7,0XBE,0XF7,0X49,0X4A,0XBE,0XF7,0X9E,0XF7,
0XBE,0XF7,0XBE,0XF7,0XBE,0XF7,0XBE,0XF7,0XBE,0XF7,0XBE,0XF7,0XBE,0XF7,0XBE,0XF7,
0XBE,0XF7,0X9E,0XF7,0XDF,0XFF,0X69,0X4A,0X49,0X4A,0X49,0X4A,0X49,0X4A,0X49,0X4A,
0X49,0X4A,0X49,0X4A,0X49,0X4A,0X49,0X4A,0X49,0X4A,0X49,0X4A,0X49,0X4A,0X49,0X4A,
0X49,0X4A,0X49,0X4A,0X49,0X4A,0X49,0X4A,0X08,0X42,0X28,0X42,0X28,0X42,0X28,0X42,
0X28,0X42,0X69,0X4A,0XBE,0XF7,0X9E,0XF7,0XBE,0XF7,0XBE,0XF7,0XBE,0XF7,0XBE,0XF7,
0XBE,0XF7,0XBE,0XF7,0XBE,0XF7,0XBE,0XF7,0XBE,0XF7,0XBE,0XF7,0X9E,0XF7,0X18,0XC6,
0X38,0XC6,0X38,0XC6,0X38,0XC6,0X38,0XC6,0X38,0XC6,0X38,0XC6,0XF3,0X9C,0X69,0X4A,
0X49,0X4A,0X49,0X4A,0X49,0X4A,0X49,0X4A,0X49,0X4A,0X49,0X4A,0X49,0X4A,0X49,0X4A,
0X49,0X4A,0X49,0X4A,0X69,0X4A,0X38,0XC6,0X38,0XC6,0X38,0XC6,0XBE,0XF7,0XBE,0XF7,
0XBE,0XF7,0XBE,0XF7,0XBE,0XF7,0XBE,0XF7,0XBE,0XF7,0XBE,0XF7,0XBE,0XF7,0XBE,0XF7,
0XBE,0XF7,0XBE,0XF7,0XBE,0XF7,0XBE,0XF7,0XBE,0XF7,0XBE,0XF7,0XBE,0XF7,0XBE,0XF7,
0XBE,0XF7,0XBE,0XF7,0XD6,0XB5,0XCB,0X5A,0X49,0X4A,0X49,0X4A,0X49,0X4A,0X49,0X4A,
0X49,0X4A,0X49,0X4A,0X49,0X4A,0X49,0X4A,0X49,0X4A,0X28,0X42,0X6D,0X6B,0XBE,0XF7,
0XBE,0XF7,0XBE,0XF7,0XBE,0XF7,0XBE,0XF7,0XBE,0XF7,0XBE,0XF7,0XBE,0XF7,0XBE,0XF7,
0XBE,0XF7,0XBE,0XF7,0XBE,0XF7,0XBE,0XF7,0XBE,0XF7,0XBE,0XF7,0XBE,0XF7,0XBE,0XF7,
0XBE,0XF7,0XBE,0XF7,0XBE,0XF7,0XBE,0XF7,0XBE,0XF7,0XBE,0XF7,0X9E,0XF7,0X34,0XA5,
0X49,0X4A,0X49,0X4A,0X49,0X4A,0X49,0X4A,0X49,0X4A,0X49,0X4A,0X49,0X4A,0X49,0X4A,
0X49,0X4A,0X49,0X4A,0XBE,0XF7,0XBE,0XF7,0XBE,0XF7,0XBE,0XF7,0XBE,0XF7,0XBE,0XF7,
0XBE,0XF7,0XBE,0XF7,0XBE,0XF7,0XBE,0XF7,0XBE,0XF7,0XBE,0XF7,0XBE,0XF7,0XBE,0XF7,
0XBE,0XF7,0XBE,0XF7,0XBE,0XF7,0XBE,0XF7,0XBE,0XF7,0XBE,0XF7,0XBE,0XF7,0XBE,0XF7,
0XBE,0XF7,0XBE,0XF7,0XBE,0XF7,0X9E,0XF7,0X1C,0XE7,0X49,0X4A,0X49,0X4A,0X49,0X4A,
0X49,0X4A,0X49,0X4A,0X49,0X4A,0X49,0X4A,0X49,0X4A,0X8A,0X52,0XAA,0X52,0XBE,0XF7,
0XBE,0XF7,0XBE,0XF7,0XBE,0XF7,0XBE,0XF7,0XBE,0XF7,0XBE,0XF7,0XBE,0XF7,0XBE,0XF7,
0XBE,0XF7,0XBE,0XF7,0XBE,0XF7,0XBE,0XF7,0XBE,0XF7,0XBE,0XF7,0XBE,0XF7,0XBE,0XF7,
0XBE,0XF7,0XBE,0XF7,0XBE,0XF7,0XBE,0XF7,0XBE,0XF7,0XBE,0XF7,0XBE,0XF7,0XBE,0XF7,
0X5C,0XE7,0X69,0X4A,0X49,0X4A,0X49,0X4A,0X49,0X4A,0X49,0X4A,0X49,0X4A,0X49,0X4A,
0X49,0X4A,0X49,0X4A,0X69,0X4A,0X49,0X4A,0XBE,0XF7,0X49,0X4A,0XBE,0XF7,0XBE,0XF7,
0XBE,0XF7,0XBE,0XF7,0XBE,0XF7,0XBE,0XF7,0XBE,0XF7,0XBE,0XF7,0XBE,0XF7,0XBE,0XF7,
0XBE,0XF7,0XBE,0XF7,0XBE,0XF7,0XBE,0XF7,0XBE,0XF7,0XBE,0XF7,0XBE,0XF7,0XBE,0XF7,
0XBE,0XF7,0XBE,0XF7,0XBE,0XF7,0XBE,0XF7,0XBE,0XF7,0X9E,0XEF,0X69,0X4A,0X69,0X4A,
0X49,0X4A,0X49,0X4A,0X49,0X4A,0X49,0X4A,0X49,0X4A,0X8A,0X52,0X49,0X4A,0X49,0X4A,
0X49,0X4A,0X49,0X4A,0XBE,0XF7,0XBE,0XF7,0XBE,0XF7,0XBE,0XF7,0XBE,0XF7,0XBE,0XF7,
0XBE,0XF7,0XBE,0XF7,0XBE,0XF7,0XBE,0XF7,0XBE,0XF7,0XBE,0XF7,0XBE,0XF7,0XBE,0XF7,
0XBE,0XF7,0XBE,0XF7,0XBE,0XF7,0XBE,0XF7,0XBE,0XF7,0XBE,0XF7,0XBE,0XF7,0XBE,0XF7,
0XBE,0XF7,0XBE,0XF7,0XDF,0XFF,0X69,0X4A,0X49,0X4A,0X49,0X4A,0X49,0X4A,0X69,0X4A,
0X69,0X4A,0X49,0X4A,0XDE,0XF7,0XDE,0XF7,0XDE,0XF7,0XDE,0XF7,0XBE,0XF7,0XBE,0XF7,
0XBE,0XF7,0XBE,0XF7,0XBE,0XF7,0XBE,0XF7,0XBE,0XF7,0XBE,0XF7,0XBE,0XF7,0XBE,0XF7,
0XBE,0XF7,0XBE,0XF7,0XBE,0XF7,0XBE,0XF7,0XBE,0XF7,0XBE,0XF7,0XBE,0XF7,0XBE,0XF7,
0XBE,0XF7,0XBE,0XF7,0XBE,0XF7,0XBE,0XF7,0XBE,0XF7,0XBE,0XF7,0XBE,0XF7,0X69,0X4A,
0X49,0X4A,0X49,0X4A,0X49,0X4A,0X49,0X4A,0X6D,0X6B,0XFB,0XDE,0XBE,0XF7,0XBE,0XF7,
0XBE,0XF7,0XBE,0XF7,0XBE,0XF7,0XBE,0XF7,0XBE,0XF7,0XBE,0XF7,0XBE,0XF7,0XBE,0XF7,
0XBE,0XF7,0XBE,0XF7,0XBE,0XF7,0XBE,0XF7,0XBE,0XF7,0XBE,0XF7,0XBE,0XF7,0XBE,0XF7,
0XBE,0XF7,0XBE,0XF7,0XBE,0XF7,0XBE,0XF7,0XBE,0XF7,0XBE,0XF7,0XBE,0XF7,0XBE,0XF7,
0XBE,0XF7,0XBE,0XF7,0X55,0XAD,0X69,0X4A,0X49,0X4A,0X49,0X4A,0X49,0X4A,0X50,0X84,
0X14,0XA5,0XBE,0XF7,0XBE,0XF7,0XBE,0XF7,0XBE,0XF7,0XBE,0XF7,0XBE,0XF7,0XBE,0XF7,
0XBE,0XF7,0XBE,0XF7,0XBE,0XF7,0XBE,0XF7,0XBE,0XF7,0XBE,0XF7,0XBE,0XF7,0XBE,0XF7,
0XBE,0XF7,0XBE,0XF7,0XBE,0XF7,0XBE,0XF7,0XBE,0XF7,0XBE,0XF7,0XBE,0XF7,0XBE,0XF7,
0XBE,0XF7,0XBE,0XF7,0XBE,0XF7,0XBE,0XF7,0XDF,0XFF,0XDF,0XFF,0X49,0X4A,0X49,0X4A,
0X49,0X4A,0X49,0X4A,0X28,0X42,0XDA,0XD6,0XBE,0XF7,0XBE,0XF7,0XBE,0XF7,0XBE,0XF7,
0XBE,0XF7,0XBE,0XF7,0XBE,0XF7,0XBE,0XF7,0XBE,0XF7,0XBE,0XF7,0XBE,0XF7,0XBE,0XF7,
0XBE,0XF7,0XBE,0XF7,0XBE,0XF7,0XBE,0XF7,0XBE,0XF7,0XBE,0XF7,0XBE,0XF7,0XBE,0XF7,
0XBE,0XF7,0XBE,0XF7,0XBE,0XF7,0XBE,0XF7,0XBE,0XF7,0XBE,0XF7,0X9E,0XEF,0XDF,0XF7,
0X1C,0XE7,0X49,0X4A,0X49,0X4A,0X49,0X4A,0X49,0X4A,0X48,0X42,0XFF,0XFF,0X9E,0XF7,
0XBE,0XF7,0XBE,0XF7,0XBE,0XF7,0XBE,0XF7,0XBE,0XF7,0XBE,0XF7,0XBE,0XF7,0XBE,0XF7,
0XBE,0XF7,0XBE,0XF7,0XBE,0XF7,0XBE,0XF7,0XBE,0XF7,0XBE,0XF7,0XBE,0XF7,0XBE,0XF7,
0XBE,0XF7,0XBE,0XF7,0XBE,0XF7,0XBE,0XF7,0XBE,0XF7,0XBE,0XF7,0XBE,0XF7,0XBE,0XF7,
0XBE,0XF7,0XBE,0XF7,0XD7,0XBD,0X69,0X4A,0X69,0X4A,0X49,0X4A,0X49,0X4A,0X49,0X4A,
0X49,0X4A,0XBE,0XF7,0X9E,0XF7,0X9E,0XF7,0XBE,0XF7,0XBE,0XF7,0XBE,0XF7,0XBE,0XF7,
0XBE,0XF7,0XBE,0XF7,0XBE,0XF7,0XBE,0XF7,0XBE,0XF7,0XBE,0XF7,0XBE,0XF7,0XBE,0XF7,
0XBE,0XF7,0XBE,0XF7,0XBE,0XF7,0XBE,0XF7,0XBE,0XF7,0XBE,0XF7,0XBE,0XF7,0XBE,0XF7,
0XBE,0XF7,0XBE,0XF7,0XBE,0XF7,0XBE,0XF7,0XBE,0XF7,0XBE,0XF7,0X7D,0XEF,0XDF,0XFF,
0X9E,0XF7,0X9E,0XF7,0X9E,0XF7,0X9E,0XF7,0X9E,0XF7,0XDF,0XFF,0XBE,0XF7,0XBE,0XF7,
0XBE,0XF7,0XBE,0XF7,0XBE,0XF7,0XBE,0XF7,0XBE,0XF7,0XBE,0XF7,0XBE,0XF7,0XBE,0XF7,
0XBE,0XF7,0XBE,0XF7,0XBE,0XF7,0XBE,0XF7,0XBE,0XF7,0XBE,0XF7,0XBE,0XF7,0XBE,0XF7,
0XBE,0XF7,0XBE,0XF7,0XBE,0XF7,0XBE,0XF7,0XBE,0XF7,0XBE,0XF7,0XBE,0XF7,0XBE,0XF7,
0XBE,0XF7,0XBE,0XF7,0XBE,0XF7,0XBE,0XF7,0XBE,0XF7,0XBE,0XF7,0XBE,0XF7,0XBE,0XF7,
0XBE,0XF7,0XBE,0XF7,0XBE,0XF7,0XBE,0XF7,0XBE,0XF7,0XBE,0XF7,0XBE,0XF7,0XBE,0XF7,
0XBE,0XF7,0XBE,0XF7,0XBE,0XF7,0XBE,0XF7,0XBE,0XF7,0XBE,0XF7,0XBE,0XF7,0XBE,0XF7,
0XBE,0XF7,0XBE,0XF7,0XBE,0XF7,0XBE,0XF7,0XBE,0XF7,0XBE,0XF7,0XBE,0XF7,0XBE,0XF7,
0XBE,0XF7,0XBE,0XF7,0XBE,0XF7,0XBE,0XF7,0XBE,0XF7,0XBE,0XF7,0XBE,0XF7,0XBE,0XF7,
0XBE,0XF7,0XBE,0XF7,0XBE,0XF7,0XBE,0XF7,0XBE,0XF7,0XBE,0XF7,0XBE,0XF7,0XBE,0XF7,
0XBE,0XF7,0XBE,0XF7,0XBE,0XF7,0XBE,0XF7,0XBE,0XF7,0XBE,0XF7,0XBE,0XF7,0XBE,0XF7,
0XBE,0XF7,0XBE,0XF7,0XBE,0XF7,0XBE,0XF7,0XBE,0XF7,0XBE,0XF7,0XBE,0XF7,0XBE,0XF7,
0XBE,0XF7,0XBE,0XF7,0XBE,0XF7,0XBE,0XF7,0XBE,0XF7,0XBE,0XF7,0XBE,0XF7,0XBE,0XF7,
0XBE,0XF7,0XBE,0XF7,0XBE,0XF7,0XBE,0XF7,0XBE,0XF7,0XBE,0XF7,0XBE,0XF7,0XBE,0XF7,
0XBE,0XF7,0XBE,0XF7,0XBE,0XF7,0XBE,0XF7,0XBE,0XF7,0XBE,0XF7,0XBE,0XF7,0XBE,0XF7,
0XBE,0XF7,0XBE,0XF7,0XBE,0XF7,0XBE,0XF7,0XBE,0XF7,0XBE,0XF7,0XBE,0XF7,0XBE,0XF7,
0XBE,0XF7,0XBE,0XF7,0XBE,0XF7,0XBE,0XF7,0XBE,0XF7,0XBE,0XF7,0XBE,0XF7,0XBE,0XF7,
0XBE,0XF7,0XBE,0XF7,0XBE,0XF7,0XBE,0XF7,0XBE,0XF7,0XBE,0XF7,0XBE,0XF7,0XBE,0XF7,
0XBE,0XF7,0XBE,0XF7,0XBE,0XF7,0XBE,0XF7,0XBE,0XF7,0XBE,0XF7,0XBE,0XF7,0XBE,0XF7,
0XBE,0XF7,0XBE,0XF7,0XBE,0XF7,0XBE,0XF7,0XBE,0XF7,0XBE,0XF7,0XBE,0XF7,0XBE,0XF7,
0XBE,0XF7,0XBE,0XF7,0XBE,0XF7,0XBE,0XF7,0XBE,0XF7,0XBE,0XF7,0XBE,0XF7,0XBE,0XF7,
0XBE,0XF7,0XBE,0XF7,0XBE,0XF7,0XBE,0XF7,0XBE,0XF7,0XBE,0XF7,0XBE,0XF7,0XBE,0XF7,
0XBE,0XF7,0XBE,0XF7,0XBE,0XF7,0XBE,0XF7,0XBE,0XF7,0XBE,0XF7,0XBE,0XF7,0XBE,0XF7,
0XBE,0XF7,0XBE,0XF7,0XBE,0XF7,0XBE,0XF7,0XBE,0XF7,0XBE,0XF7,0XBE,0XF7,0XBE,0XF7,
0XBE,0XF7,0XBE,0XF7,0XBE,0XF7,0XBE,0XF7,0XBE,0XF7,0XBE,0XF7,0XBE,0XF7,0XBE,0XF7,
0XBE,0XF7,0XBE,0XF7,0XBE,0XF7,0XBE,0XF7,0XBE,0XF7,0XBE,0XF7,0XBE,0XF7,0XBE,0XF7,
0XBE,0XF7,0XBE,0XF7,0XBE,0XF7,0XBE,0XF7,0XBE,0XF7,0XBE,0XF7,0XBE,0XF7,0XBE,0XF7,
0XBE,0XF7,0XBE,0XF7,0XBE,0XF7,0XBE,0XF7,0XBE,0XF7,0XBE,0XF7,0XBE,0XF7,0XBE,0XF7,
0XBE,0XF7,0XBE,0XF7,0XBE,0XF7,0XBE,0XF7,0XBE,0XF7,0XBE,0XF7,0XBE,0XF7,0XBE,0XF7,
0XBE,0XF7,0XBE,0XF7,0XBE,0XF7,0XBE,0XF7,0XBE,0XF7,0XBE,0XF7,0XBE,0XF7,0XBE,0XF7,
0XBE,0XF7,0XBE,0XF7,0XBE,0XF7,0XBE,0XF7,0XBE,0XF7,0XBE,0XF7,0XBE,0XF7,0XBE,0XF7,
0XBE,0XF7,0XBE,0XF7,0XBE,0XF7,0XBE,0XF7,0XBE,0XF7,0XBE,0XF7,0XBE,0XF7,0XBE,0XF7,
0XBE,0XF7,0XBE,0XF7,0XBE,0XF7,0XBE,0XF7,0XBE,0XF7,0XBE,0XF7,0XBE,0XF7,0XBE,0XF7,
0XBE,0XF7,0XBE,0XF7,0XBE,0XF7,0XBE,0XF7,0XBE,0XF7,0XBE,0XF7,0XBE,0XF7,0XBE,0XF7,
};

const unsigned char gImage_plane[2560] = { /* 0X00,0X10,0X28,0X00,0X20,0X00,0X01,0X1B, */
0X00,0X00,0X00,0X00,0X00,0X00,0X00,0X00,0X00,0X00,0X00,0X00,0X00,0X00,0X00,0X00,
0X00,0X00,0X00,0X00,0X00,0X00,0X00,0X00,0X00,0X00,0X00,0X00,0X00,0X00,0X00,0X00,
0X00,0X00,0X00,0X00,0X00,0X00,0X00,0X00,0X00,0X00,0X00,0X00,0X00,0X00,0X00,0X00,
0X00,0X00,0X00,0X00,0X00,0X00,0X00,0X00,0X00,0X00,0X00,0X00,0X00,0X00,0X00,0X00,
0X00,0X00,0X00,0X00,0X00,0X00,0X00,0X00,0X00,0X00,0X00,0X00,0X00,0X00,0X00,0X00,
0X00,0X00,0X00,0X00,0X00,0X00,0X00,0X00,0X00,0X00,0X00,0X00,0X00,0X00,0X00,0X00,
0X00,0X00,0X00,0X00,0X00,0X00,0X00,0X00,0X00,0X00,0X00,0X00,0X00,0X00,0X00,0X00,
0X00,0X00,0X00,0X00,0X17,0X55,0X00,0X00,0X41,0X00,0X17,0X5D,0X00,0X00,0X00,0X00,
0X00,0X00,0X00,0X00,0X00,0X00,0X00,0X00,0X00,0X00,0X00,0X00,0X00,0X00,0X00,0X00,
0X00,0X00,0X00,0X00,0X00,0X00,0X00,0X00,0X00,0X00,0X00,0X00,0X00,0X00,0X00,0X00,
0X00,0X00,0X00,0X00,0X00,0X00,0X00,0X00,0X00,0X00,0X00,0X00,0X00,0X00,0X00,0X00,
0X00,0X00,0X00,0X00,0X00,0X00,0X00,0X00,0X00,0X00,0X00,0X00,0X00,0X00,0X00,0X00,
0X00,0X00,0X04,0X09,0X75,0X44,0X3E,0XCF,0XD6,0X54,0X75,0X44,0X2A,0X1A,0X00,0X00,
0X00,0X00,0X00,0X00,0X00,0X00,0X00,0X00,0X00,0X00,0X00,0X00,0X00,0X00,0X00,0X00,
0X00,0X00,0X00,0X00,0X00,0X00,0X00,0X00,0X00,0X00,0X00,0X00,0X00,0X00,0X00,0X00,
0X00,0X00,0X00,0X00,0X00,0X00,0X00,0X00,0X00,0X00,0X00,0X00,0X00,0X00,0X00,0X00,
0X00,0X00,0X00,0X00,0X00,0X00,0X00,0X00,0X00,0X00,0X00,0X00,0X00,0X00,0X00,0X00,
0X00,0X00,0XCD,0X32,0XD7,0X54,0X7E,0XDF,0X17,0X5D,0XB6,0X4C,0X91,0X33,0X00,0X00,
0X00,0X00,0X00,0X00,0X00,0X00,0X00,0X00,0X00,0X00,0X00,0X00,0X00,0X00,0X00,0X00,
0X00,0X00,0X00,0X00,0X00,0X00,0X00,0X00,0X00,0X00,0X00,0X00,0X00,0X00,0X00,0X00,
0X00,0X00,0X00,0X00,0X00,0X00,0X00,0X00,0X00,0X00,0X00,0X00,0X00,0X00,0X00,0X00,
0X00,0X00,0X00,0X00,0X00,0X00,0X00,0X00,0X00,0X00,0X00,0X00,0X00,0X00,0X00,0X00,
0X00,0X00,0X18,0XC6,0X3C,0XEF,0X5D,0XEF,0XDB,0XDE,0XBA,0XDE,0X59,0XCE,0X00,0X00,
0X00,0X00,0X00,0X00,0X00,0X00,0X00,0X00,0X00,0X00,0X00,0X00,0X00,0X00,0X00,0X00,
0X00,0X00,0X00,0X00,0X00,0X00,0X00,0X00,0X00,0X00,0X00,0X00,0X00,0X00,0X00,0X00,
0X00,0X00,0X00,0X00,0X00,0X00,0X00,0X00,0X00,0X00,0X00,0X00,0X00,0X00,0X00,0X00,
0X00,0X00,0X00,0X00,0X00,0X00,0X00,0X00,0X62,0X08,0X00,0X00,0X00,0X00,0X00,0X00,
0X00,0X00,0X58,0XCE,0X1C,0XE7,0XDF,0XFF,0XFB,0XDE,0X9A,0XD6,0X59,0XCE,0X00,0X00,
0X00,0X00,0X00,0X00,0X20,0X00,0X82,0X08,0X00,0X00,0X00,0X00,0X00,0X00,0X00,0X00,
0X00,0X00,0X00,0X00,0X00,0X00,0X00,0X00,0X00,0X00,0X00,0X00,0X00,0X00,0X00,0X00,
0X00,0X00,0X00,0X00,0X00,0X00,0X00,0X00,0X00,0X00,0X00,0X00,0X00,0X00,0X29,0X32,
0X16,0X75,0XBA,0X75,0X96,0X4C,0X34,0X3C,0X75,0X54,0XF3,0X2B,0XF3,0X33,0XF3,0X33,
0XEF,0X12,0X75,0X44,0X17,0X65,0X98,0X8D,0X34,0X4C,0X54,0X44,0X75,0X44,0X30,0X1B,
0XF3,0X33,0XF3,0X2B,0XF3,0X2B,0X54,0X5C,0X34,0X3C,0XD6,0X54,0XDA,0X75,0XF6,0X74,
0X8B,0X3A,0X00,0X00,0X00,0X00,0X00,0X00,0X00,0X00,0X00,0X00,0X00,0X00,0X00,0X00,
0X00,0X00,0X00,0X00,0X00,0X00,0X00,0X00,0X32,0X64,0XDA,0X7D,0X96,0X44,0XD9,0X8D,
0X98,0X95,0X14,0X2C,0X75,0X44,0X34,0X3C,0X70,0X33,0X71,0X33,0XB2,0X2B,0X14,0X2C,
0X51,0X23,0X55,0X3C,0XB9,0X75,0X3D,0XCF,0XF7,0X5C,0XB6,0X4C,0X55,0X44,0XB2,0X2B,
0XF3,0X2B,0X92,0X2B,0X91,0X33,0X70,0X3B,0X55,0X3C,0X75,0X44,0XF6,0X5C,0XBC,0XBE,
0X78,0X7D,0XF7,0X54,0XDA,0X7D,0X6F,0X4B,0X00,0X00,0X00,0X00,0X00,0X00,0X00,0X00,
0X00,0X00,0X00,0X00,0X1A,0X9E,0X55,0X3C,0X54,0X3C,0X55,0X44,0X35,0X3C,0X5D,0XE7,
0XD8,0XAD,0XFC,0XD6,0X34,0X3C,0X75,0X3C,0X75,0X44,0X14,0X34,0X14,0X34,0X14,0X34,
0XB2,0X2B,0X55,0X44,0X99,0X6D,0X3D,0XC7,0XF7,0X5C,0XB6,0X4C,0X55,0X44,0XF3,0X33,
0X14,0X34,0X14,0X34,0X14,0X2C,0X75,0X44,0X75,0X44,0XBC,0XBE,0X9B,0XC6,0XD8,0XAD,
0XDC,0XCE,0X55,0X3C,0X55,0X3C,0X54,0X3C,0X96,0X44,0X57,0X7D,0X00,0X00,0X00,0X00,
0X00,0X00,0X9C,0XA6,0X55,0X3C,0XD2,0X3B,0X95,0X5C,0X58,0X7D,0X14,0X34,0X55,0X3C,
0X7E,0XE7,0X9E,0XEF,0XDC,0XC6,0X55,0X3C,0X55,0X3C,0X14,0X34,0X14,0X34,0X14,0X34,
0XB2,0X2B,0X75,0X3C,0X99,0X6D,0X1D,0XC7,0XF7,0X5C,0XB6,0X4C,0X55,0X3C,0XF3,0X33,
0X14,0X34,0X14,0X34,0XD3,0X2B,0X75,0X44,0X34,0X34,0X9E,0XEF,0XBF,0XEF,0X17,0X6D,
0X55,0X44,0X3A,0XA6,0X75,0X4C,0X95,0X64,0X50,0X33,0X75,0X44,0X56,0X8D,0X00,0X00,
0X00,0X00,0X37,0X6D,0X55,0X3C,0X0F,0X3B,0X55,0X3C,0XF7,0X64,0X9E,0XE7,0XDF,0XF7,
0X13,0X44,0X34,0X34,0XBC,0XBE,0X55,0X3C,0X55,0X3C,0X14,0X34,0X14,0X34,0X14,0X34,
0XB2,0X2B,0X75,0X44,0XB5,0X5C,0XD5,0X74,0X95,0X64,0X34,0X44,0X75,0X44,0X13,0X34,
0X14,0X34,0X14,0X34,0XB3,0X2B,0X75,0X44,0X34,0X34,0X78,0X7D,0X55,0X44,0X13,0X44,
0XDF,0XF7,0XDF,0XF7,0X34,0X34,0X54,0X3C,0X70,0X3B,0X55,0X3C,0XB6,0X4C,0X00,0X00,
0X00,0X00,0X6C,0X12,0X75,0X44,0X91,0X33,0X75,0X3C,0X55,0X3C,0X76,0X9D,0XBF,0XEF,
0X18,0XB6,0XF3,0X33,0X0B,0X1A,0X91,0X33,0X30,0X33,0X75,0X4C,0XD2,0X43,0X13,0X3C,
0X92,0X2B,0X75,0X44,0X0F,0X33,0XD9,0X9D,0XB8,0X95,0X13,0X54,0X55,0X3C,0XF3,0X33,
0X14,0X3C,0X33,0X54,0X54,0X44,0X30,0X33,0XEF,0X2A,0XCE,0X22,0X77,0X85,0X1D,0XDF,
0X9E,0XEF,0X33,0X5C,0X55,0X3C,0XB6,0X44,0X34,0X3C,0X54,0X3C,0XC4,0X08,0X00,0X00,
0X00,0X00,0X00,0X00,0X14,0X2C,0X75,0X44,0XB9,0X85,0XD6,0X54,0XB6,0X64,0XB9,0X7D,
0XFA,0X95,0X14,0X34,0X75,0X44,0X34,0X3C,0X55,0X3C,0X35,0X34,0X14,0X34,0X14,0X34,
0X71,0X23,0XB6,0X4C,0X19,0XA6,0XDF,0XFF,0XBB,0XC6,0X16,0X7D,0X58,0X65,0XB2,0X2B,
0X14,0X34,0X14,0X34,0XF3,0X2B,0X95,0X44,0X55,0X3C,0X54,0X3C,0X95,0X4C,0X7B,0XAE,
0X58,0X6D,0X17,0X65,0XD6,0X54,0XB4,0X6C,0X75,0X44,0X35,0X34,0X00,0X00,0X00,0X00,
0X00,0X00,0X00,0X00,0X00,0X00,0X14,0X2C,0X90,0X4B,0X14,0X34,0X14,0X34,0X14,0X34,
0XF3,0X2B,0XF3,0X2B,0XF3,0X2B,0XF3,0X2B,0X14,0X34,0X92,0X23,0X92,0X2B,0X91,0X23,
0X50,0X23,0XB6,0X4C,0XF2,0X53,0XD6,0X74,0XB5,0X6C,0X74,0X6C,0X38,0X65,0X71,0X23,
0X92,0X23,0X92,0X2B,0XB2,0X23,0X55,0X44,0XF3,0X2B,0XF3,0X2B,0XF3,0X2B,0XF3,0X2B,
0X14,0X34,0X14,0X34,0XF4,0X2B,0X91,0X43,0X14,0X2C,0X00,0X00,0X00,0X00,0X00,0X00,
0X00,0X00,0X00,0X00,0X00,0X00,0X00,0X00,0X00,0X00,0X00,0X00,0X00,0X00,0X00,0X00,
0X00,0X00,0X00,0X00,0X00,0X00,0X00,0X00,0X00,0X00,0X00,0X00,0X00,0X00,0X00,0X00,
0X00,0X00,0X75,0X44,0X5A,0XAE,0X1A,0XA6,0X7B,0XB6,0X77,0X8D,0X17,0X5D,0X00,0X00,
0X00,0X00,0X00,0X00,0X00,0X00,0X00,0X00,0X00,0X00,0X00,0X00,0X00,0X00,0X00,0X00,
0X00,0X00,0X00,0X00,0X00,0X00,0X00,0X00,0X00,0X00,0X00,0X00,0X00,0X00,0X00,0X00,
0X00,0X00,0X00,0X00,0X00,0X00,0X00,0X00,0X00,0X00,0X00,0X00,0X00,0X00,0X00,0X00,
0X00,0X00,0X00,0X00,0X00,0X00,0X00,0X00,0X00,0X00,0X00,0X00,0X00,0X00,0X00,0X00,
0X00,0X00,0XF2,0X43,0X5A,0XAE,0X3A,0XA6,0X7B,0XB6,0X77,0X8D,0XD6,0X54,0X00,0X00,
0X00,0X00,0X00,0X00,0X00,0X00,0X00,0X00,0X00,0X00,0X00,0X00,0X00,0X00,0X00,0X00,
0X00,0X00,0X00,0X00,0X00,0X00,0X00,0X00,0X00,0X00,0X00,0X00,0X00,0X00,0X00,0X00,
0X00,0X00,0X00,0X00,0X00,0X00,0X00,0X00,0X00,0X00,0X00,0X00,0X00,0X00,0X00,0X00,
0X00,0X00,0X00,0X00,0X00,0X00,0X00,0X00,0X00,0X00,0X00,0X00,0X00,0X00,0X00,0X00,
0X00,0X00,0X2A,0X1A,0XD5,0X7C,0XF9,0X9D,0X36,0X85,0X91,0X4B,0X50,0X33,0X00,0X00,
0X00,0X00,0X00,0X00,0X00,0X00,0X00,0X00,0X00,0X00,0X00,0X00,0X00,0X00,0X00,0X00,
0X00,0X00,0X00,0X00,0X00,0X00,0X00,0X00,0X00,0X00,0X00,0X00,0X00,0X00,0X00,0X00,
0X00,0X00,0X00,0X00,0X00,0X00,0X00,0X00,0X00,0X00,0X00,0X00,0X00,0X00,0X00,0X00,
0X00,0X00,0X00,0X00,0X00,0X00,0X00,0X00,0X00,0X00,0X00,0X00,0X00,0X00,0X00,0X00,
0X00,0X00,0XC3,0X08,0X38,0X65,0X3B,0X96,0X1A,0X8E,0X38,0X65,0XE9,0X19,0X00,0X00,
0X00,0X00,0X00,0X00,0X00,0X00,0X00,0X00,0X00,0X00,0X00,0X00,0X00,0X00,0X00,0X00,
0X00,0X00,0X00,0X00,0X00,0X00,0X00,0X00,0X00,0X00,0X00,0X00,0X00,0X00,0X00,0X00,
0X00,0X00,0X00,0X00,0X00,0X00,0X00,0X00,0X00,0X00,0X00,0X00,0X00,0X00,0X00,0X00,
0X00,0X00,0X00,0X00,0X00,0X00,0X00,0X00,0X00,0X00,0X00,0X00,0X00,0X00,0X00,0X00,
0X00,0X00,0X00,0X00,0XB6,0X54,0X1D,0XC7,0X38,0X65,0XB6,0X54,0X00,0X00,0X00,0X00,
0X00,0X00,0X00,0X00,0X00,0X00,0X00,0X00,0X00,0X00,0X00,0X00,0X00,0X00,0X00,0X00,
0X00,0X00,0X00,0X00,0X00,0X00,0X00,0X00,0X00,0X00,0X00,0X00,0X00,0X00,0X00,0X00,
0X00,0X00,0X00,0X00,0X00,0X00,0X00,0X00,0X00,0X00,0X00,0X00,0X00,0X00,0X00,0X00,
0X00,0X00,0X00,0X00,0X00,0X00,0X00,0X00,0X00,0X00,0X00,0X00,0X00,0X00,0X00,0X00,
0X00,0X00,0X00,0X00,0XF2,0X4B,0X3E,0XBF,0X99,0X75,0X34,0X54,0X00,0X00,0X00,0X00,
0X00,0X00,0X00,0X00,0X00,0X00,0X00,0X00,0X00,0X00,0X00,0X00,0X00,0X00,0X00,0X00,
0X00,0X00,0X00,0X00,0X00,0X00,0X00,0X00,0X00,0X00,0X00,0X00,0X00,0X00,0X00,0X00,
0X00,0X00,0X00,0X00,0X00,0X00,0X00,0X00,0X00,0X00,0X00,0X00,0X00,0X00,0X00,0X00,
0X00,0X00,0X00,0X00,0X00,0X00,0X00,0X00,0X00,0X00,0X00,0X00,0X00,0X00,0X00,0X00,
0X00,0X00,0X00,0X00,0XB6,0X4C,0X3E,0XC7,0X58,0X65,0X96,0X4C,0X00,0X00,0X00,0X00,
0X00,0X00,0X00,0X00,0X00,0X00,0X00,0X00,0X00,0X00,0X00,0X00,0X00,0X00,0X00,0X00,
0X00,0X00,0X00,0X00,0X00,0X00,0X00,0X00,0X00,0X00,0X00,0X00,0X00,0X00,0X00,0X00,
0X00,0X00,0X00,0X00,0X00,0X00,0X00,0X00,0X00,0X00,0X00,0X00,0X00,0X00,0X00,0X00,
0X00,0X00,0X00,0X00,0X00,0X00,0X00,0X00,0X00,0X00,0X00,0X00,0X00,0X00,0X00,0X00,
0X00,0X00,0X00,0X00,0XB6,0X4C,0XFD,0XBE,0X38,0X65,0X55,0X44,0X00,0X00,0X00,0X00,
0X00,0X00,0X00,0X00,0X00,0X00,0X00,0X00,0X00,0X00,0X00,0X00,0X00,0X00,0X00,0X00,
0X00,0X00,0X00,0X00,0X00,0X00,0X00,0X00,0X00,0X00,0X00,0X00,0X00,0X00,0X00,0X00,
0X00,0X00,0X00,0X00,0X00,0X00,0X00,0X00,0X00,0X00,0X00,0X00,0X00,0X00,0X00,0X00,
0X00,0X00,0X00,0X00,0X00,0X00,0X00,0X00,0X00,0X00,0X00,0X00,0X00,0X00,0X00,0X00,
0X00,0X00,0X00,0X00,0X75,0X44,0XFD,0XBE,0X17,0X65,0XEE,0X2A,0X00,0X00,0X00,0X00,
0X00,0X00,0X00,0X00,0X00,0X00,0X00,0X00,0X00,0X00,0X00,0X00,0X00,0X00,0X00,0X00,
0X00,0X00,0X00,0X00,0X00,0X00,0X00,0X00,0X00,0X00,0X00,0X00,0X00,0X00,0X00,0X00,
0X00,0X00,0X00,0X00,0X00,0X00,0X00,0X00,0X00,0X00,0X00,0X00,0X00,0X00,0X00,0X00,
0X00,0X00,0X00,0X00,0X00,0X00,0X00,0X00,0X00,0X00,0X00,0X00,0X00,0X00,0X00,0X00,
0X00,0X00,0X00,0X00,0X4F,0X33,0XB5,0X6C,0X33,0X54,0X26,0X11,0X00,0X00,0X00,0X00,
0X00,0X00,0X00,0X00,0X00,0X00,0X00,0X00,0X00,0X00,0X00,0X00,0X00,0X00,0X00,0X00,
0X00,0X00,0X00,0X00,0X00,0X00,0X00,0X00,0X00,0X00,0X00,0X00,0X00,0X00,0X00,0X00,
0X00,0X00,0X00,0X00,0X00,0X00,0X00,0X00,0X00,0X00,0X00,0X00,0X00,0X00,0X00,0X00,
0X00,0X00,0X00,0X00,0X00,0X00,0X00,0X00,0X00,0X00,0X00,0X00,0X00,0X00,0X00,0X00,
0X00,0X00,0X00,0X00,0XE9,0X19,0XD6,0X5C,0X95,0X4C,0X00,0X00,0X00,0X00,0X00,0X00,
0X00,0X00,0X00,0X00,0X00,0X00,0X00,0X00,0X00,0X00,0X00,0X00,0X00,0X00,0X00,0X00,
0X00,0X00,0X00,0X00,0X00,0X00,0X00,0X00,0X00,0X00,0X00,0X00,0X00,0X00,0X00,0X00,
0X00,0X00,0X00,0X00,0X00,0X00,0X00,0X00,0X00,0X00,0X00,0X00,0X00,0X00,0X00,0X00,
0X00,0X00,0X00,0X00,0X00,0X00,0X00,0X00,0X00,0X00,0X00,0X00,0X00,0X00,0X41,0X00,
0X2C,0X5B,0X3D,0XD7,0X51,0X1B,0XD6,0X54,0X54,0X44,0XF4,0X2B,0X9F,0XEF,0X49,0X42,
0X00,0X00,0X00,0X00,0X00,0X00,0X00,0X00,0X00,0X00,0X00,0X00,0X00,0X00,0X00,0X00,
0X00,0X00,0X00,0X00,0X00,0X00,0X00,0X00,0X00,0X00,0X00,0X00,0X00,0X00,0X00,0X00,
0X00,0X00,0X00,0X00,0X00,0X00,0X00,0X00,0X00,0X00,0X00,0X00,0X00,0X00,0X00,0X00,
0X00,0X00,0X00,0X00,0X00,0X00,0X00,0X00,0X20,0X00,0XD6,0X5C,0X90,0X53,0XF9,0XA5,
0X39,0XB6,0XB0,0X5B,0X30,0X23,0XD6,0X5C,0X34,0X3C,0XB2,0X33,0X11,0X6C,0X98,0X8D,
0X9A,0XC6,0XD1,0X5B,0X96,0X4C,0XA3,0X10,0X00,0X00,0X00,0X00,0X00,0X00,0X00,0X00,
0X00,0X00,0X00,0X00,0X00,0X00,0X00,0X00,0X00,0X00,0X00,0X00,0X00,0X00,0X00,0X00,
0X00,0X00,0X00,0X00,0X00,0X00,0X00,0X00,0X00,0X00,0X00,0X00,0X00,0X00,0X00,0X00,
0X00,0X00,0X00,0X00,0X00,0X00,0X00,0X00,0X86,0X21,0X75,0X44,0X7E,0XDF,0XDC,0XC6,
0X3D,0XD7,0X7E,0XDF,0X55,0X3C,0XD6,0X54,0XF3,0X33,0X55,0X3C,0X9E,0XDF,0X5B,0XA6,
0X7E,0XE7,0X7E,0XE7,0X34,0X34,0X90,0X53,0X00,0X00,0X00,0X00,0X00,0X00,0X00,0X00,
0X00,0X00,0X00,0X00,0X00,0X00,0X00,0X00,0X00,0X00,0X00,0X00,0X00,0X00,0X00,0X00,
0X00,0X00,0X00,0X00,0X00,0X00,0X00,0X00,0X00,0X00,0X00,0X00,0X00,0X00,0X00,0X00,
0X00,0X00,0X00,0X00,0X00,0X00,0X00,0X00,0X00,0X00,0XA8,0X11,0X76,0X9D,0X5A,0XB6,
0X7E,0XDF,0X9F,0XDF,0XD3,0X2B,0XB6,0X54,0X50,0X1B,0XD3,0X2B,0XBF,0XE7,0X5A,0XA6,
0XFC,0XD6,0X55,0X9D,0X67,0X09,0X00,0X00,0X00,0X00,0X00,0X00,0X00,0X00,0X00,0X00,
0X00,0X00,0X00,0X00,0X00,0X00,0X00,0X00,0X00,0X00,0X00,0X00,0X00,0X00,0X00,0X00,
0X00,0X00,0X00,0X00,0X00,0X00,0X00,0X00,0X00,0X00,0X00,0X00,0X00,0X00,0X00,0X00,
0X00,0X00,0X00,0X00,0X00,0X00,0X00,0X00,0X00,0X00,0X00,0X00,0X00,0X00,0X00,0X00,
0X00,0X00,0X00,0X00,0X00,0X00,0XF2,0X4B,0X67,0X09,0X00,0X00,0X00,0X00,0X00,0X00,
0X00,0X00,0X00,0X00,0X00,0X00,0X00,0X00,0X00,0X00,0X00,0X00,0X00,0X00,0X00,0X00,
0X00,0X00,0X00,0X00,0X00,0X00,0X00,0X00,0X00,0X00,0X00,0X00,0X00,0X00,0X00,0X00,
0X00,0X00,0X00,0X00,0X00,0X00,0X00,0X00,0X00,0X00,0X00,0X00,0X00,0X00,0X00,0X00,
0X00,0X00,0X00,0X00,0X00,0X00,0X00,0X00,0X00,0X00,0X00,0X00,0X00,0X00,0X00,0X00,
0X00,0X00,0X00,0X00,0X00,0X00,0X13,0X4C,0X87,0X11,0X00,0X00,0X00,0X00,0X00,0X00,
0X00,0X00,0X00,0X00,0X00,0X00,0X00,0X00,0X00,0X00,0X00,0X00,0X00,0X00,0X00,0X00,
0X00,0X00,0X00,0X00,0X00,0X00,0X00,0X00,0X00,0X00,0X00,0X00,0X00,0X00,0X00,0X00,
0X00,0X00,0X00,0X00,0X00,0X00,0X00,0X00,0X00,0X00,0X00,0X00,0X00,0X00,0X00,0X00,
0X00,0X00,0X00,0X00,0X00,0X00,0X00,0X00,0X00,0X00,0X00,0X00,0X00,0X00,0X00,0X00,
0X00,0X00,0X00,0X00,0X00,0X00,0X00,0X00,0X00,0X00,0X00,0X00,0X00,0X00,0X00,0X00,
0X00,0X00,0X00,0X00,0X00,0X00,0X00,0X00,0X00,0X00,0X00,0X00,0X00,0X00,0X00,0X00,
0X00,0X00,0X00,0X00,0X00,0X00,0X00,0X00,0X00,0X00,0X00,0X00,0X00,0X00,0X00,0X00,
};

const unsigned char gImage_missile[960] = { /* 0X00,0X10,0X0C,0X00,0X28,0X00,0X01,0X1B, */
0X00,0X00,0X00,0X00,0X00,0X00,0X00,0X00,0X00,0X00,0X00,0X00,0X00,0X00,0X00,0X00,
0X00,0X00,0X00,0X00,0X00,0X00,0X00,0X00,0X00,0X00,0X00,0X00,0X00,0X00,0X00,0X00,
0X00,0X00,0X00,0X00,0X00,0X00,0X00,0X00,0X00,0X00,0X00,0X00,0X00,0X00,0X00,0X00,
0X00,0X00,0X00,0X00,0X00,0X00,0X00,0X00,0X00,0X00,0X00,0X08,0X00,0X08,0X00,0X00,
0X00,0X00,0X00,0X00,0X00,0X00,0X00,0X00,0X00,0X00,0X00,0X00,0X00,0X00,0X00,0X00,
0X00,0X00,0X60,0X20,0X60,0X20,0X00,0X00,0X00,0X00,0X00,0X00,0X00,0X00,0X00,0X00,
0X00,0X00,0X00,0X00,0X00,0X00,0X00,0X00,0X00,0X00,0X00,0X31,0X00,0X31,0X00,0X00,
0X00,0X00,0X00,0X00,0X00,0X00,0X00,0X00,0X00,0X00,0X00,0X00,0X00,0X00,0X00,0X00,
0X00,0X00,0X00,0X51,0X00,0X51,0X00,0X00,0X00,0X00,0X00,0X00,0X00,0X00,0X00,0X00,
0X00,0X00,0X00,0X00,0X00,0X00,0X00,0X00,0X00,0X08,0X20,0X72,0X20,0X72,0X00,0X08,
0X00,0X00,0X00,0X00,0X00,0X00,0X00,0X00,0X00,0X00,0X00,0X00,0X00,0X00,0X00,0X00,
0X60,0X08,0X20,0X9A,0X20,0X9A,0X60,0X08,0X00,0X00,0X00,0X00,0X00,0X00,0X00,0X00,
0X00,0X00,0X00,0X00,0X00,0X00,0X00,0X00,0X60,0X20,0X22,0XAB,0X20,0XBB,0X60,0X20,
0X00,0X00,0X00,0X00,0X00,0X00,0X00,0X00,0X00,0X00,0X00,0X00,0X00,0X00,0X00,0X00,
0X00,0X41,0X20,0XCB,0X20,0XCB,0X00,0X41,0X00,0X00,0X00,0X00,0X00,0X00,0X00,0X00,
0X00,0X00,0X00,0X00,0X00,0X00,0X00,0X00,0X80,0X51,0X42,0XDC,0X42,0XDC,0X80,0X51,
0X00,0X00,0X00,0X00,0X00,0X00,0X00,0X00,0X00,0X00,0X00,0X00,0X00,0X00,0X00,0X00,
0X20,0X72,0XC0,0XFC,0XC0,0XFC,0X20,0X72,0X00,0X00,0X00,0X00,0X00,0X00,0X00,0X00,
0X00,0X00,0X00,0X00,0X00,0X00,0X00,0X08,0XA2,0X8A,0XC0,0XFC,0XC0,0XFC,0XA2,0X8A,
0X00,0X08,0X00,0X00,0X00,0X00,0X00,0X00,0X00,0X00,0X00,0X00,0X00,0X00,0X60,0X08,
0X22,0X9B,0X40,0XFC,0XC0,0XFC,0X22,0XAB,0X60,0X08,0X00,0X00,0X00,0X00,0X00,0X00,
0X00,0X00,0X00,0X00,0X00,0X00,0X60,0X20,0X22,0XAB,0X40,0XFC,0X40,0XFC,0X20,0XBB,
0X60,0X20,0X00,0X00,0X00,0X00,0X00,0X00,0X00,0X00,0X00,0X00,0X00,0X00,0X00,0X31,
0X42,0XBC,0X40,0XFC,0XC0,0XFC,0X42,0XBC,0X00,0X31,0X00,0X00,0X00,0X00,0X00,0X00,
0X00,0X00,0X00,0X00,0X00,0X00,0X00,0X41,0X42,0XBC,0X40,0XFC,0X40,0XFC,0X42,0XDC,
0X80,0X51,0X00,0X00,0X00,0X00,0X00,0X00,0X00,0X00,0X00,0X00,0X00,0X00,0X80,0X51,
0X42,0XDC,0X40,0XFC,0XC0,0XFC,0X42,0XDC,0XA0,0X62,0X00,0X00,0X00,0X00,0X00,0X00,
0X00,0X00,0X00,0X00,0X00,0X08,0X20,0X72,0XC0,0XFC,0XC0,0XFC,0XC0,0XFC,0XC0,0XFC,
0XA2,0X8A,0X00,0X08,0X00,0X00,0X00,0X00,0X00,0X00,0X00,0X00,0X60,0X08,0XA2,0X8A,
0XC0,0XFC,0XC0,0XFC,0XC0,0XFC,0XC0,0XFC,0XA2,0X8A,0X60,0X08,0X00,0X00,0X00,0X00,
0X00,0X00,0X00,0X00,0X60,0X20,0X22,0X9B,0XC0,0XFD,0XC0,0XFC,0XC0,0XFC,0XC0,0XFD,
0X22,0XAB,0X60,0X20,0X00,0X00,0X00,0X00,0X00,0X00,0X00,0X00,0X00,0X31,0X20,0XBB,
0XC0,0XFD,0XC4,0XFC,0XC4,0XFC,0XC0,0XFD,0X42,0XBC,0X00,0X31,0X00,0X00,0X00,0X00,
0X00,0X00,0X00,0X00,0X00,0X41,0X42,0XBC,0XC4,0XFC,0X64,0XFE,0X64,0XFE,0XC0,0XFD,
0X42,0XDC,0X00,0X41,0X00,0X00,0X00,0X00,0X00,0X00,0X00,0X00,0X80,0X51,0XC0,0XFD,
0X64,0XFE,0X64,0XFE,0XC4,0XFC,0X64,0XFE,0XC0,0XFC,0XA0,0X62,0X00,0X00,0X00,0X00,
0X00,0X00,0X60,0X08,0XA2,0X8A,0XC0,0XFD,0X64,0XFE,0X64,0XFE,0XC8,0XFD,0X64,0XFE,
0XC0,0XFD,0XA2,0X8A,0X60,0X08,0X00,0X00,0X00,0X00,0X60,0X20,0X22,0XAB,0X64,0XFE,
0X64,0XFE,0X64,0XFE,0X64,0XFE,0X64,0XFE,0X64,0XFE,0X22,0XAB,0X60,0X20,0X00,0X00,
0X00,0X00,0X00,0X41,0X42,0XDC,0XE8,0XFE,0XE8,0XFE,0XE8,0XFE,0XE8,0XFE,0XE8,0XFE,
0XE8,0XFE,0X42,0XDC,0X00,0X41,0X00,0X00,0X00,0X08,0X80,0X51,0XC0,0XFD,0XE8,0XFE,
0XEC,0XFE,0XEC,0XFE,0XEC,0XFE,0XE8,0XFE,0XE8,0XFE,0XC0,0XFD,0X80,0X51,0X00,0X08,
0X60,0X08,0XA2,0X8A,0XE8,0XFE,0XEC,0XFE,0XEC,0XFE,0XEC,0XFE,0XEC,0XFE,0XEC,0XFE,
0XEC,0XFE,0XE8,0XFE,0XA2,0X8A,0X60,0X08,0X60,0X20,0X22,0XAB,0XEC,0XFE,0XEE,0XFF,
0X73,0XFF,0X73,0XFF,0X73,0XFF,0XEE,0XFF,0X73,0XFF,0XEC,0XFE,0X22,0XAB,0X60,0X20,
0X00,0X31,0X20,0XBB,0X73,0XFF,0X73,0XFF,0XF1,0XFF,0X73,0XFF,0X73,0XFF,0X73,0XFF,
0X73,0XFF,0X73,0XFF,0X20,0XBB,0X00,0X31,0X00,0X31,0X20,0XCB,0X73,0XFF,0X73,0XFF,
0XF5,0XFF,0XF5,0XFF,0XF5,0XFF,0XF5,0XFF,0X73,0XFF,0X73,0XFF,0X20,0XCB,0X00,0X31,
0X00,0X31,0X20,0XCB,0XF5,0XFF,0XF7,0XFF,0XF7,0XFF,0XF5,0XFF,0XF7,0XFF,0X73,0XFF,
0XF7,0XFF,0XF5,0XFF,0X20,0XCB,0X00,0X31,0X00,0X31,0X20,0XBB,0XF5,0XFF,0XF7,0XFF,
0XF7,0XFF,0XF5,0XFF,0XF5,0XFF,0XF7,0XFF,0XF7,0XFF,0XF5,0XFF,0X20,0XBB,0X00,0X31,
0X60,0X20,0X22,0X9B,0X73,0XFF,0XF7,0XFF,0XFB,0XFF,0XF7,0XFF,0XFB,0XFF,0XF7,0XFF,
0XF7,0XFF,0X73,0XFF,0X22,0X9B,0X60,0X20,0X60,0X08,0X80,0X61,0X64,0XFE,0XFB,0XFF,
0XFB,0XFF,0XFB,0XFF,0XF7,0XFF,0XFB,0XFF,0XFB,0XFF,0X64,0XFE,0X80,0X61,0X60,0X08,
0X00,0X00,0X00,0X31,0X22,0XAB,0X73,0XFF,0XFB,0XFF,0XFB,0XFF,0XFB,0XFF,0XFB,0XFF,
0X73,0XFF,0X22,0XAB,0X00,0X31,0X00,0X00,0X00,0X00,0X00,0X08,0X00,0X41,0X20,0XBB,
0XEC,0XFE,0XFB,0XFF,0XF7,0XFF,0XEC,0XFE,0X22,0XAB,0X00,0X41,0X00,0X08,0X00,0X00,
0X00,0X00,0X00,0X00,0X60,0X08,0X00,0X31,0XA2,0X8A,0X22,0XAB,0X22,0XAB,0XA2,0X8A,
0X00,0X31,0X60,0X08,0X00,0X00,0X00,0X00,0X00,0X00,0X00,0X00,0X00,0X00,0X00,0X00,
0X60,0X08,0X00,0X31,0X60,0X20,0X60,0X08,0X00,0X00,0X00,0X00,0X00,0X00,0X00,0X00,
};

// 定义屏幕宽度和高度
#define SCREEN_WIDTH 240
#define SCREEN_HEIGHT 320

// 障碍物的宽度和高度
uint16_t OBSTACLE_WIDTH;
uint16_t OBSTACLE_HEIGHT;
// 障碍物速度
#define OBSTACLE_SPEED 1
#define MAX_SPEED 10
#define MIN_SPEED -10

uint32_t last_slide_time = 0; // 上一次滑动的时间戳
uint32_t last_update_time = 0; // 上次速度更新的时间戳
#define INERTIA_DECAY 1   // 惯性衰减（每秒减速量）
#define SLIDE_TIMEOUT 2000   // 停止滑动后的超时时间（ms）
#define WINDOW_TIMEOUT 1000

//选手的宽度和高度
uint16_t PLAYER_WIDTH;
uint16_t PLAYER_HEIGHT;
#define JUMP_TIMEOUT 1000
#define TERMINAL 10
////飞机大战参数
//#define PLANE_WIDTH 40
//#define PLANE_HEIGHT 32
//
//#define MISSILE_WIDTH 12
//#define MISSILE_HEIGHT 40
uint8_t level = 0;
uint8_t mode = 0;
int16_t speed = 0;
uint16_t timer = 0;
// 按钮参数
const uint16_t screen_width = 240;  // 假设屏幕宽度为 240 像素
const uint16_t screen_height = 320; // 假设屏幕高度为 320 像素
const uint16_t button_width = 60;   // 每个按钮的宽度
const uint16_t button_height = 30;  // 每个按钮的高度
const uint8_t corner_radius = 10;   // 按钮圆角半径
uint8_t jump = 0;
uint32_t last_jump_time = 0;

// 定义人物初始位置
int16_t player_x ; // 人物起始位置（水平居中）
uint16_t player_y ;   // 人物起始位置（靠近底部）

// 障碍物结构体
typedef struct {
    int16_t x; // 障碍物的 x 坐标
    int16_t y; // 障碍物的 y 坐标
    uint16_t color; // 障碍物的颜色
} Obstacle;

// 障碍物数组
#define MAX_OBSTACLES 3
Obstacle obstacles[MAX_OBSTACLES];

// 用于存储触摸点的起始和当前坐标
static int16_t start_x = -1, start_y = -1; // 触摸起点
static int16_t current_x = -1, current_y = -1; // 当前触摸点

// 滑动方向枚举
typedef enum {
    SLIDE_NONE,
    SLIDE_UP,
    SLIDE_DOWN,
    SLIDE_LEFT,
    SLIDE_RIGHT
} SlideDirection;

// 滑动事件队列
#define SLIDE_HISTORY_SIZE 10
typedef struct {
    uint32_t timestamp;       // 滑动时间戳
    SlideDirection direction; // 滑动方向
} SlideEvent;
SlideEvent slide_history[SLIDE_HISTORY_SIZE] = {0}; // 存储滑动时间和方向
uint8_t slide_index = 0;

// 随机数初始化
void Random_Init() {
    srand(HAL_GetTick()); // 使用当前系统时间作为随机种子
}

// 用于检查两个矩形是否重叠
uint8_t Check_Overlap(Obstacle a, Obstacle b) {
    return (a.x < b.x + OBSTACLE_WIDTH &&
            a.x + OBSTACLE_WIDTH > b.x &&
            a.y < b.y + OBSTACLE_HEIGHT &&
            a.y + OBSTACLE_HEIGHT > b.y);
}

void Init_Obstacles() {
	if(mode == 1){
		OBSTACLE_WIDTH = 12;
		OBSTACLE_HEIGHT = 40;
	}else{
		OBSTACLE_WIDTH = 20;
		OBSTACLE_HEIGHT = 20;
	}
    for (int i = 0; i < MAX_OBSTACLES; i++) {
        uint8_t overlap; // 标志变量，用于检查是否重叠
        do {
            overlap = 0;

            // 随机生成障碍物的坐标和颜色
            obstacles[i].x = rand() % (SCREEN_WIDTH - OBSTACLE_WIDTH);
            obstacles[i].y = - rand() % (2 * OBSTACLE_HEIGHT);
            obstacles[i].color = (rand() % 2) ? RED : GREEN;

            // 检查是否与已有的障碍物发生重叠
            for (int j = 0; j < i; j++) {
                if (Check_Overlap(obstacles[i], obstacles[j])== 1) {
                    overlap = 1; // 如果发生重叠，重新生成
                    break;
                }
            }
        } while (overlap); // 如果重叠，则重新生成
    }
}

// 绘制人物
void Draw_Player(int x, int y) {
	uint32_t current_time = HAL_GetTick();
	if(mode == 0){
		if(current_time - last_jump_time > JUMP_TIMEOUT){
			LCD_ShowPic(x,y,PLAYER_WIDTH,PLAYER_HEIGHT,gImage_dinosaur);
		}else{
			LCD_ShowPic(x,y,PLAYER_WIDTH,PLAYER_HEIGHT,gImage_dinosaur_jump);
		}
	}else{
//		PLAYER_WIDTH = 40;
//		PLAYER_HEIGHT = 32;
		if(current_time - last_jump_time > JUMP_TIMEOUT){
			LCD_ShowPic(x,y,PLAYER_WIDTH,PLAYER_HEIGHT,gImage_plane);
		}else{
			LCD_ShowPic(x,y,PLAYER_WIDTH,PLAYER_HEIGHT,gImage_dinosaur_jump);
		}
	}
}

// 清除人物
void Clear_Player(int x, int y) {
	uint32_t current_time = HAL_GetTick();
	if(mode == 0){
		if(current_time - last_jump_time > JUMP_TIMEOUT){
			LCD_Fill(x, y, x + PLAYER_WIDTH, y + PLAYER_HEIGHT, WHITE); // 用背景色覆盖人物
		}else{
			LCD_Fill(x, y, x + PLAYER_HEIGHT - 1, y + PLAYER_WIDTH, WHITE); // 用背景色覆盖人物
		}
    }else{
    	if(current_time - last_jump_time > JUMP_TIMEOUT){
    		LCD_Fill(x, y, x + PLAYER_WIDTH, y + PLAYER_HEIGHT, BLACK); // 用背景色覆盖人物
    	}else{
    		LCD_Fill(x, y, x + PLAYER_WIDTH, y + PLAYER_HEIGHT, BLACK); // 用背景色覆盖人物
    	}
    }
}

// 绘制障碍物
void Draw_Obstacle(Obstacle *obstacle) {
	if((obstacle->x >= 0)&(obstacle->x <= 240)&(obstacle->y >= 0)&(obstacle->y <= SCREEN_HEIGHT - 10 - button_height - OBSTACLE_HEIGHT)){
		if(mode == 0){
			LCD_Fill(obstacle->x, obstacle->y, obstacle->x + OBSTACLE_WIDTH - 1, obstacle->y + OBSTACLE_HEIGHT - 1, obstacle->color);
		}else{
			LCD_ShowPic(obstacle->x, obstacle->y, OBSTACLE_WIDTH, OBSTACLE_HEIGHT, gImage_missile);
		}
  }
}

// 更新障碍物位置
void Update_Obstacles() {
    if(level >= TERMINAL * MAX_OBSTACLES){
    	if(timer <= 120){
			LCD_ShowString(100, 150, 12 * 9, 24, 24, "YOU WIN !");
    	}else{
			LCD_ShowString(100, 150, 12 * 9, 24, 24, "TIME OUT!");
    	}
		return;
    }
    for (int i = 0; i < MAX_OBSTACLES; i++) {
        // 如果障碍物已超出屏幕，则重新生成
        if (obstacles[i].y >= SCREEN_HEIGHT + 10 * OBSTACLE_HEIGHT) {
            obstacles[i].x = rand() % (SCREEN_WIDTH - OBSTACLE_WIDTH); // 随机生成 x 坐标
            obstacles[i].y = - rand() %  (2*OBSTACLE_HEIGHT); // 障碍物重新出现在屏幕上方
            level = level + 1;
        } else {
        	//检测是否发生碰撞
        	if(player_x < obstacles[i].x + OBSTACLE_WIDTH
        			&& player_x + PLAYER_WIDTH > obstacles[i].x
					&&  player_y < obstacles[i].y + OBSTACLE_HEIGHT
					&& player_y + PLAYER_HEIGHT > obstacles[i].y ){
        		uint32_t current_time = HAL_GetTick();
        		//检测是否处于跳跃状态
        		if(current_time - last_jump_time > JUMP_TIMEOUT){
        			speed = 0;
        	    	LCD_ShowString(100, 150, 12 * 8, 24, 24, "YOU LOSE");
//        	    	level = 0;
        		}else{
            		obstacles[i].y += speed; // 跳跃状态
            		Draw_Player(player_x, player_y);
        		}
        	}else{
        		obstacles[i].y += speed; // 向下移动
            }
        }

        Draw_Obstacle(&obstacles[i]); // 绘制障碍物
    }
}

// 清除障碍物区域
void Clear_Obstacles() {
    for (int i = 0; i < MAX_OBSTACLES; i++) {
    	if(mode == 0)
    	{
    		if((obstacles[i].x >= 0)&(obstacles[i].x <= 240)&(obstacles[i].y >= 0)&(obstacles[i].y <= SCREEN_HEIGHT - 10 - button_height - OBSTACLE_HEIGHT) ){
    			LCD_Fill(obstacles[i].x, obstacles[i].y, obstacles[i].x + OBSTACLE_WIDTH - 1, obstacles[i].y + OBSTACLE_HEIGHT - 1, WHITE);
    		}
    	}else{
    		if((obstacles[i].x >= 0)&(obstacles[i].x <= 240)&(obstacles[i].y >= 0)&(obstacles[i].y <= SCREEN_HEIGHT - 10 - button_height - OBSTACLE_HEIGHT) ){
    		    			LCD_Fill(obstacles[i].x, obstacles[i].y, obstacles[i].x + OBSTACLE_WIDTH - 1, obstacles[i].y + OBSTACLE_HEIGHT - 1, BLACK);
    		    		}
    	}
    }
}

// 添加滑动事件到队列
void Record_Slide_Event(SlideDirection direction) {
    uint32_t timestamp = HAL_GetTick();
    slide_history[slide_index].timestamp = timestamp;
    slide_history[slide_index].direction = direction;
    slide_index = (slide_index + 1) % SLIDE_HISTORY_SIZE;
    // 更新最后滑动时间
    last_slide_time = timestamp;
}

// 分析滑动事件，计算速度增量
int Analyze_Slide_Events(void) {
    uint32_t now = HAL_GetTick();
    int16_t delta_speed = 0;

    // 遍历滑动事件队列，计算在 timeout 窗口内的速度增量
    for (uint8_t i = 0; i < SLIDE_HISTORY_SIZE; i++) {
        if ((slide_history[i].timestamp > 0) && (now - slide_history[i].timestamp <= WINDOW_TIMEOUT)) {
            if (slide_history[i].direction == SLIDE_UP) {
                delta_speed += 1; // 上滑增加速度
            } else if (slide_history[i].direction == SLIDE_DOWN) {
                delta_speed -= 1; // 下滑减少速度
            }
        }
    }

    return delta_speed;
}

// 更新速度
void Update_Speed(void) {
    uint32_t now = HAL_GetTick();

    // 如果有滑动操作，根据方向和频率调整速度
    if (now - last_slide_time <= SLIDE_TIMEOUT) {
    	if(now - last_update_time >= WINDOW_TIMEOUT){
			int16_t delta_speed = Analyze_Slide_Events();
			// 根据滑动影响调整速度
			speed += delta_speed ;
			if (speed > MAX_SPEED) speed = MAX_SPEED;
			if (speed < MIN_SPEED) speed = MIN_SPEED;
		    last_update_time = now;
    	}
    } else {
        // 停止滑动后，模拟惯性减速
//        uint32_t elapsed_time = (now - last_update_time) / 1000.0;
        if (speed > 0) {
//            speed -= INERTIA_DECAY * elapsed_time; // 前进方向减速
        	speed -= 0.5;
            if (speed < 0) speed = 0;
        } else if (speed < 0) {
//            speed += INERTIA_DECAY * elapsed_time; // 后退方向减速
        	speed += 0.5;
            if (speed > 0) speed = 0;
        }
    }
    // 当速度为 0 时显示提示信息
    if (speed == 0) {
        LCD_ShowString(0, 0, 200, 16, 16, "Stopped ");
    }else if(speed > 0){
        LCD_ShowString(0, 0, 200, 16, 16, "Forward ");
    }else{
        LCD_ShowString(0, 0, 200, 16, 16, "Backward");
    }
}

/* USER CODE END PD */

/* USER CODE BEGIN PM */
//清空屏幕并在右上角显�?"RST"
void Load_Drow_Dialog(void)
{
 	POINT_COLOR=BLUE;//设置字体为蓝�?
	LCD_ShowString(lcddev.width-24,0,200,16,16,"RST");//显示清屏区域
  	POINT_COLOR=BLUE;//设置画笔蓝色
  	Draw_Dashed_Line(120, 0, 320, 30, 10);
  	uint16_t button_y = screen_height - button_height - 5; // 按钮的 Y 坐标

    // 按钮颜色
    uint16_t button_color = RED;
    uint16_t text_color = WHITE;

// 	POINT_COLOR=WHITE;
    // 绘制 "LEFT" 按钮
    uint16_t left_x1 = 10;
    uint16_t left_x2 = left_x1 + button_width;
    LCD_DrawButton(left_x1, button_y, left_x2, button_y + button_height, corner_radius, button_color, "LEFT", text_color);

    button_color = YELLOW;
    // 绘制 "RIGHT" 按钮
    uint16_t right_x1 = screen_width - button_width - 10;
    uint16_t right_x2 = right_x1 + button_width;
    LCD_DrawButton(right_x1, button_y, right_x2, button_y + button_height, corner_radius, button_color, "RIGHT", text_color);

    button_color = GREEN;
    // 绘制 "JUMP" 按钮
    uint16_t jump_x1 = (screen_width - button_width) / 2;
    uint16_t jump_x2 = jump_x1 + button_width;
    LCD_DrawButton(jump_x1, button_y, jump_x2, button_y + button_height, corner_radius, button_color, "JUMP", text_color);
    //My dinosaur
    Draw_Player(player_x,player_y);

}

void Draw_Dashed_Line(uint16_t x, uint16_t y_start, uint16_t y_end, uint16_t dash_length, uint16_t gap_length) {
    uint16_t y = y_start;

    while (y < y_end) {
        uint16_t y_dash_end = y + dash_length;
        if (y_dash_end > y_end) {
            y_dash_end = y_end;
        }

        // 绘制一段线
        LCD_DrawLine(x, y, x, y_dash_end); // 在LCD上绘制一段线

        // 跳过间隔部分
        y = y_dash_end + gap_length;
    }
}

void LCD_FillRoundedRectangle(uint16_t sx, uint16_t sy, uint16_t ex, uint16_t ey, uint16_t radius, uint16_t color) {
    // 填充矩形中间部分
    LCD_Fill(sx + radius, sy, ex - radius, ey, color);

    // 填充矩形顶部和底部的中间部分
    LCD_Fill(sx, sy + radius, ex, ey - radius, color);

    // 绘制并填充四个圆角
    for (int y = 0; y < radius; y++) {
        for (int x = 0; x < radius; x++) {
            if ((x * x + y * y) <= (radius * radius)) {
                LCD_Fast_DrawPoint(sx + radius - x, sy + radius - y, color); // 左上
                LCD_Fast_DrawPoint(sx + radius - x, ey - radius + y, color); // 左下
                LCD_Fast_DrawPoint(ex - radius + x, sy + radius - y, color); // 右上
                LCD_Fast_DrawPoint(ex - radius + x, ey - radius + y, color); // 右下
            }
        }
    }
}

void LCD_DrawButton(uint16_t sx, uint16_t sy, uint16_t ex, uint16_t ey, uint16_t radius, uint16_t color, const char *text, uint16_t text_color) {
	// 绘制圆角矩形并填充颜色
    LCD_FillRoundedRectangle(sx, sy, ex, ey, radius, color);
    // 在按钮中心显示文字
    uint16_t text_x = sx + ((ex - sx) - (strlen(text) * 8)) / 2; // 文字居中
    uint16_t text_y = sy + ((ey - sy) - 16) / 2;                // 文字垂直居中
    LCD_ShowString2(text_x, text_y, 40, 20, 16, (uint8_t *)text);

}

void screen_norm_print(){
//	LCD_Clear(WHITE);//清屏
	POINT_COLOR=BLUE;//设置字体为蓝色
	LCD_ShowString(lcddev.width-24,0,200,16,16,"RST");//显示清屏区域
	LCD_ShowString(0,0,200,24,24, "SHOW PICTURE");
	LCD_ShowString(60,60,200,24,24, "SEND MESSAGE");
	LCD_ShowString(0, lcddev.height-24, 200, 16, 16, STATE);
	POINT_COLOR=RED;//设置画笔为红色

}

// 检测滑动方向
SlideDirection Detect_Slide_Direction(int16_t start_x, int16_t start_y, int16_t current_x, int16_t current_y) {
    int16_t dx = current_x - start_x;
    int16_t dy = current_y - start_y;

    // 设置滑动阈值，避免误判
    int16_t threshold = 20; // 像素

    if (abs(dx) > abs(dy)) {
        if (dx > threshold) {
            return SLIDE_RIGHT; // 向右滑动
        } else if (dx < -threshold) {
            return SLIDE_LEFT; // 向左滑动
        }
    } else {
        if (dy > threshold) {
            return SLIDE_DOWN; // 向下滑动
        } else if (dy < -threshold) {
            return SLIDE_UP; // 向上滑动
        }
    }

    return SLIDE_NONE; // 未检测到滑动
}

void reset(){
	  if(mode == 0){
		  LCD_Clear(WHITE);
			PLAYER_WIDTH = 40;
			PLAYER_HEIGHT = 37;
	  }else{
		  	LCD_Clear(BLACK);
			PLAYER_WIDTH = 40;
			PLAYER_HEIGHT = 32;
	  }
	  player_x = (screen_width - button_width) / 2; // 人物起始位置（水平居中）
	  player_y = screen_height - button_height - 10 - PLAYER_HEIGHT;   // 人物起始位置（靠近底部）
	  Draw_Player(player_x, player_y);
	  Init_Obstacles(); // 初始化障碍物
	  Load_Drow_Dialog();
	  last_update_time = HAL_GetTick();
	  level = 0;
	  speed = 0;
	  timer = 0;
}

//电阻触摸屏测试函�?
void rtp_test(void)
{
	u8 key;
	u8 i=0;

	while(1)
	{
	    Clear_Obstacles(); // 清除原来障碍物的区域
	    Update_Obstacles(); // 更新障碍物位置
	  	Draw_Dashed_Line(120, 0, 320, 30, 10);
        char level_str[20];
        sprintf(level_str, "Level: %d", level/MAX_OBSTACLES);
        LCD_ShowString(lcddev.width-72,20, 200, 16, 16, level_str);
        char timer_str[20];
        sprintf(timer_str, "Time: %d", timer);
        LCD_ShowString(lcddev.width-72,40, 200, 16, 16, timer_str);
	 	key=KEY_Scan(0);
		tp_dev.scan(0);
		 // 检测触摸按下
		if (tp_dev.sta & TP_PRES_DOWN) {
			if (start_x == -1 && start_y == -1) {
				// 记录起始坐标
				start_x = tp_dev.x[0];
				start_y = tp_dev.y[0];
			} else {
				// 记录当前坐标
				current_x = tp_dev.x[0];
				current_y = tp_dev.y[0];
			}
			if((tp_dev.x[0] >= 10&&tp_dev.x[0] <= 70) && (tp_dev.y[0] >= 280&&tp_dev.y[0] <= 310)){
				// 点击了 LEFT 按钮，人物左移
				Clear_Player(player_x, player_y); // 清除旧位置
				player_x -= 20;                   // 左移20像素
				if (player_x < 0) player_x = 0;   // 边界检测
				Draw_Player(player_x, player_y); // 绘制新位置
			}else if((tp_dev.x[0] >= 170&&tp_dev.x[0] <= 230) && (tp_dev.y[0] >= 280&&tp_dev.y[0] <= 310)){
				// 点击了 RIGHT 按钮，人物右移
				Clear_Player(player_x, player_y); // 清除旧位置
				player_x += 20;                   // 左移20像素
				if (player_x > SCREEN_WIDTH - PLAYER_WIDTH) player_x = SCREEN_WIDTH - PLAYER_WIDTH ;   // 边界检测
				Draw_Player(player_x, player_y); // 绘制新位置
			}else if((tp_dev.x[0] >= 90&&tp_dev.x[0] <= 150) && (tp_dev.y[0] >= 280&&tp_dev.y[0] <= 310)){
				// 点击了 RIGHT 按钮，人物右移
//				Clear_Player(player_x, player_y); // 清除旧位置
//				player_x += 20;                   // 左移20像素
//				Draw_Player(player_x, player_y); // 绘制新位置
				jump = 1;
				last_jump_time = HAL_GetTick();
				LCD_ShowPic(player_x,player_y,PLAYER_WIDTH,PLAYER_HEIGHT,gImage_dinosaur_jump);

			}
		}

		// 检测触摸松开
		if ((tp_dev.sta & TP_PRES_DOWN) == 0 && start_x != -1 && start_y != -1) {
			// 检测滑动方向
			SlideDirection direction = Detect_Slide_Direction(start_x, start_y, current_x, current_y);
			// 根据滑动方向执行操作
			switch (direction) {
				case SLIDE_UP:
					LCD_ShowString(lcddev.width-40,0,200,16,16,"UP   ");//显示清屏区域
					break;
				case SLIDE_DOWN:
					LCD_ShowString(lcddev.width-40,0,200,16,16,"DOWN ");//显示清屏区域
					break;
				case SLIDE_LEFT:
					LCD_ShowString(lcddev.width-40,0,200,16,16,"LEFT ");//显示清屏区域
					Clear_Player(player_x, player_y); // 清除旧位置
					player_x -= 20;                   // 左移20像素
					if (player_x < 0) player_x = 0;   // 边界检测
					Draw_Player(player_x, player_y); // 绘制新位置
					break;
				case SLIDE_RIGHT:
					LCD_ShowString(lcddev.width-40,0,200,16,16,"RIGHT");//显示清屏区域
					Clear_Player(player_x, player_y); // 清除旧位置
					player_x += 20;                   // 左移20像素
					if (player_x > SCREEN_WIDTH - PLAYER_WIDTH) player_x = SCREEN_WIDTH - PLAYER_WIDTH ;   // 边界检测
					Draw_Player(player_x, player_y); // 绘制新位置
					break;
				default:
					break;
			}
            if (direction == SLIDE_UP || direction == SLIDE_DOWN) {
                Record_Slide_Event(direction);  // 记录滑动事件
            }

			// 重置触摸点
			start_x = -1;
			start_y = -1;
			current_x = -1;
			current_y = -1;
		}
        // 更新速度
        Update_Speed();
        LCD_ShowString(0, 20, 200, 16, 16, "Speed:    ");
        // 显示当前速度
        char speed_str[20];
        sprintf(speed_str, "Speed: %d", speed);
        LCD_ShowString(0, 20, 200, 16, 16, speed_str);

		delay_ms(10);	//没有按键按下的时�?
		if(key==KEY0_PRES)	//KEY0按下,则执行校准程�?
		{
			reset();
//			LCD_ShowPic(40,40,12,40,gImage_missile);
		}else if(key == KEY1_PRES ){
			if(mode == 0){
				mode = 1;
			}else{
				mode = 0;
			}
			reset();
		}
		i++;
		if(i%20==0){
			LED0=!LED0;
			timer = timer + 1;
		}
	}
}

/* USER CODE END PM */

SPI_HandleTypeDef hspi1;

UART_HandleTypeDef huart1;

void SystemClock_Config(void);
static void MX_GPIO_Init(void);
static void MX_SPI1_Init(void);
static void MX_USART1_UART_Init(void);

int main(void)
{

  /* MCU Configuration--------------------------------------------------------*/

  /* Reset of all peripherals, Initializes the Flash interface and the Systick. */
  HAL_Init();

  /* USER CODE BEGIN Init */
  Stm32_Clock_Init(RCC_PLL_MUL9);   	//设置时钟,72M
	delay_init(72);               		//初始化延时函�?
//	uart_init(115200);					//初始化串�?
//	usmart_dev.init(84); 		  	  	//初始化USMART
	LED_Init();							//初始化LED
	KEY_Init();							//初始化按�?
	LCD_Init();							//初始化LCD
	tp_dev.init();				   		//触摸屏初始化
  /* USER CODE END Init */

  /* Configure the system clock */
  SystemClock_Config();

  /* Initialize all configured peripherals */
  MX_GPIO_Init();
  MX_SPI1_Init();
  MX_USART1_UART_Init();
  Random_Init(); // 初始化随机数生成器
  Init_Obstacles(); // 初始化障碍物
  if(mode == 0){
	PLAYER_WIDTH = 40;
	PLAYER_HEIGHT = 37;
  }else{
		PLAYER_WIDTH = 40;
		PLAYER_HEIGHT = 32;
  }
  player_x = (screen_width - button_width) / 2; // 人物起始位置（水平居中）
  player_y = screen_height - button_height - 10 - PLAYER_HEIGHT;   // 人物起始位置（靠近底部）
  /* USER CODE BEGIN 2 */
	LCD_ShowPic(player_x,player_y,PLAYER_WIDTH,PLAYER_HEIGHT,gImage_dinosaur);
   	Load_Drow_Dialog();
   	last_update_time = HAL_GetTick();
    rtp_test(); 					//电阻屏
  /* USER CODE END 2 */

  /* Infinite loop */

}

void SystemClock_Config(void)
{
  RCC_OscInitTypeDef RCC_OscInitStruct = {0};
  RCC_ClkInitTypeDef RCC_ClkInitStruct = {0};

  /** Initializes the RCC Oscillators according to the specified parameters
  * in the RCC_OscInitTypeDef structure.
  */
  RCC_OscInitStruct.OscillatorType = RCC_OSCILLATORTYPE_HSE;
  RCC_OscInitStruct.HSEState = RCC_HSE_ON;
  RCC_OscInitStruct.HSEPredivValue = RCC_HSE_PREDIV_DIV1;
  RCC_OscInitStruct.HSIState = RCC_HSI_ON;
  RCC_OscInitStruct.PLL.PLLState = RCC_PLL_ON;
  RCC_OscInitStruct.PLL.PLLSource = RCC_PLLSOURCE_HSE;
  RCC_OscInitStruct.PLL.PLLMUL = RCC_PLL_MUL9;
  if (HAL_RCC_OscConfig(&RCC_OscInitStruct) != HAL_OK)
  {
    Error_Handler();
  }

  /** Initializes the CPU, AHB and APB buses clocks
  */
  RCC_ClkInitStruct.ClockType = RCC_CLOCKTYPE_HCLK|RCC_CLOCKTYPE_SYSCLK
                              |RCC_CLOCKTYPE_PCLK1|RCC_CLOCKTYPE_PCLK2;
  RCC_ClkInitStruct.SYSCLKSource = RCC_SYSCLKSOURCE_PLLCLK;
  RCC_ClkInitStruct.AHBCLKDivider = RCC_SYSCLK_DIV1;
  RCC_ClkInitStruct.APB1CLKDivider = RCC_HCLK_DIV2;
  RCC_ClkInitStruct.APB2CLKDivider = RCC_HCLK_DIV1;

  if (HAL_RCC_ClockConfig(&RCC_ClkInitStruct, FLASH_LATENCY_2) != HAL_OK)
  {
    Error_Handler();
  }
}

static void MX_SPI1_Init(void)
{

  /* SPI1 parameter configuration*/
  hspi1.Instance = SPI1;
  hspi1.Init.Mode = SPI_MODE_MASTER;
  hspi1.Init.Direction = SPI_DIRECTION_2LINES;
  hspi1.Init.DataSize = SPI_DATASIZE_8BIT;
  hspi1.Init.CLKPolarity = SPI_POLARITY_LOW;
  hspi1.Init.CLKPhase = SPI_PHASE_1EDGE;
  hspi1.Init.NSS = SPI_NSS_SOFT;
  hspi1.Init.BaudRatePrescaler = SPI_BAUDRATEPRESCALER_8;
  hspi1.Init.FirstBit = SPI_FIRSTBIT_MSB;
  hspi1.Init.TIMode = SPI_TIMODE_DISABLE;
  hspi1.Init.CRCCalculation = SPI_CRCCALCULATION_DISABLE;
  hspi1.Init.CRCPolynomial = 10;
  if (HAL_SPI_Init(&hspi1) != HAL_OK)
  {
    Error_Handler();
  }

}

static void MX_USART1_UART_Init(void)
{

  huart1.Instance = USART1;
  huart1.Init.BaudRate = 115200;
  huart1.Init.WordLength = UART_WORDLENGTH_8B;
  huart1.Init.StopBits = UART_STOPBITS_1;
  huart1.Init.Parity = UART_PARITY_NONE;
  huart1.Init.Mode = UART_MODE_TX_RX;
  huart1.Init.HwFlowCtl = UART_HWCONTROL_NONE;
  huart1.Init.OverSampling = UART_OVERSAMPLING_16;
  if (HAL_UART_Init(&huart1) != HAL_OK)
  {
    Error_Handler();
  }

}

static void MX_GPIO_Init(void)
{

  /* GPIO Ports Clock Enable */
  __HAL_RCC_GPIOD_CLK_ENABLE();
  __HAL_RCC_GPIOA_CLK_ENABLE();

}

void Error_Handler(void)
{
  __disable_irq();
  while (1)
  {
  }
}
